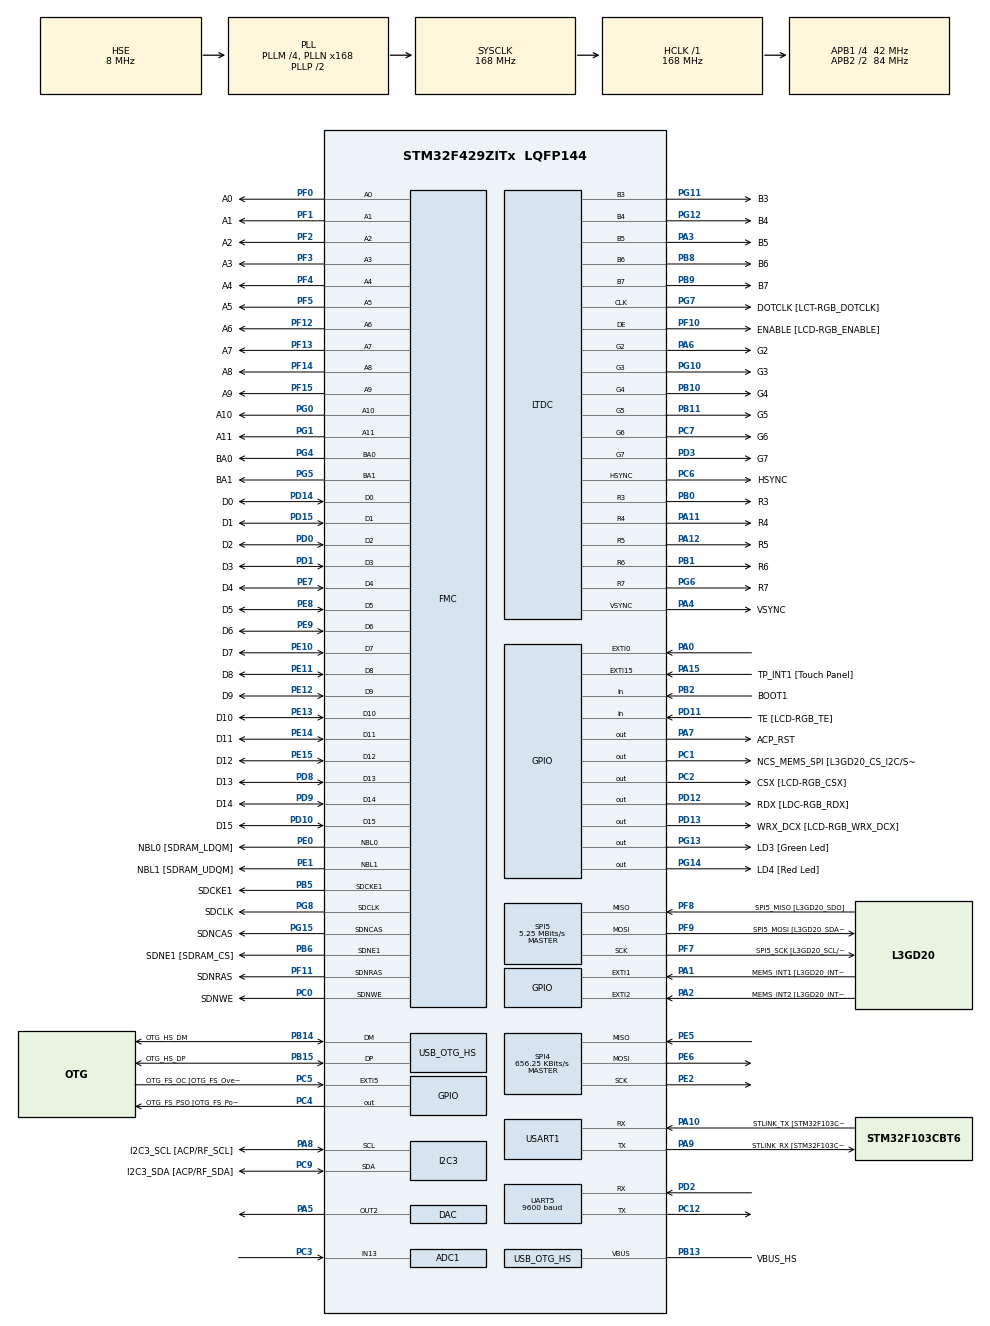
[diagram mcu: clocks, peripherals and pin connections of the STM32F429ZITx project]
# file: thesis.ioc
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ADC1.Channel-0\#ChannelRegularConversion=ADC_CHANNEL_13
ADC1.NbrOfConversionFlag=1
ADC1.Rank-0\#ChannelRegularConversion=1
ADC1.SamplingTime-0\#ChannelRegularConversion=ADC_SAMPLETIME_3CYCLES
ADC1.master=1
FMC.CASLatency1=FMC_SDRAM_CAS_LATENCY_3
FMC.ExitSelfRefreshDelay1=7
FMC.LoadToActiveDelay1=2
FMC.RCDDelay1=2
FMC.RPDelay1=2
FMC.RPDelay2=2
FMC.ReadBurst1=FMC_SDRAM_RBURST_DISABLE
FMC.ReadPipeDelay1=FMC_SDRAM_RPIPE_DELAY_1
FMC.ReadPipeDelay2=FMC_SDRAM_RPIPE_DELAY_1
FMC.RowCycleDelay1=7
FMC.RowCycleDelay2=7
FMC.SDClockPeriod1=FMC_SDRAM_CLOCK_PERIOD_2
FMC.SDClockPeriod2=FMC_SDRAM_CLOCK_PERIOD_2
FMC.SelfRefreshTime1=4
FMC.WriteRecoveryTime1=3
FREERTOS.Tasks01=defaultTask,0,4096,StartDefaultTask,Default,NULL,Dynamic,NULL,NULL
FREERTOS.configCHECK_FOR_STACK_OVERFLOW=2
FREERTOS.configTOTAL_HEAP_SIZE=32768
FREERTOS.configUSE_APPLICATION_TASK_TAG=1
FREERTOS.configUSE_COUNTING_SEMAPHORES=1
FREERTOS.configUSE_IDLE_HOOK=1
FREERTOS.configUSE_MALLOC_FAILED_HOOK=1
FREERTOS.configUSE_RECURSIVE_MUTEXES=1
LTDC.ActiveH=320
LTDC.ActiveW=240
LTDC.Alpha_L0=255
LTDC.BlendingFactor1_L0=LTDC_BLENDING_FACTOR1_PAxCA
LTDC.BlendingFactor2_L0=LTDC_BLENDING_FACTOR2_PAxCA
LTDC.FBStartAdress_L0=0xD0000000
LTDC.HBP=29
LTDC.HFP=10
LTDC.HSync=9
LTDC.ImageHeight_L0=320
LTDC.ImageWidth_L0=240
LTDC.Layers=0
LTDC.PixelFormat_L0=LTDC_PIXEL_FORMAT_RGB565
LTDC.VBP=3
LTDC.VFP=4
LTDC.VSync=1
LTDC.WindowX1_L0=239
LTDC.WindowY1_L0=319
Mcu.Family=STM32F4
Mcu.Name=STM32F429ZITx
Mcu.Package=LQFP144
NVIC.DMA2D_IRQn=true\:5\:0\:true\:false\:true\:true\:true\:true\:true
NVIC.EXTI0_IRQn=true\:5\:0\:false\:false\:true\:true\:true\:true\:true
NVIC.LTDC_IRQn=true\:5\:0\:true\:false\:true\:true\:true\:true\:true
NVIC.OTG_HS_IRQn=true\:5\:0\:false\:false\:true\:true\:true\:true\:true
NVIC.PriorityGroup=NVIC_PRIORITYGROUP_4
NVIC.TIM6_DAC_IRQn=true\:5\:0\:false\:false\:true\:false\:false\:true\:true
NVIC.TIM7_IRQn=true\:5\:0\:false\:false\:true\:true\:true\:true\:true
NVIC.TimeBase=TIM6_DAC_IRQn
NVIC.TimeBaseIP=TIM6
PA0/WKUP.GPIO_ModeDefaultEXTI=GPIO_MODE_IT_RISING
PA0/WKUP.GPIO_PuPd=GPIO_NOPULL
PA0/WKUP.Signal=GPXTI0
PA1.GPIO_Label=MEMS_INT1 [L3GD20_INT1]
PA1.GPIO_ModeDefaultEXTI=GPIO_MODE_IT_FALLING
PA1.GPIO_PuPd=GPIO_PULLUP
PA1.Signal=GPXTI1
PA10.GPIO_Label=STLINK_TX [STM32F103CBT6_PA2]
PA10.Mode=Asynchronous
PA10.Signal=USART1_RX
PA11.GPIO_Label=R4
PA11.GPIO_Mode=GPIO_MODE_AF_PP
PA11.GPIO_PuPd=GPIO_NOPULL
PA11.GPIO_Speed=GPIO_SPEED_FREQ_LOW
PA11.Mode=RGB565
PA11.Signal=LTDC_R4
PA12.GPIO_Label=R5
PA12.GPIO_Mode=GPIO_MODE_AF_PP
PA12.GPIO_PuPd=GPIO_NOPULL
PA12.GPIO_Speed=GPIO_SPEED_FREQ_LOW
PA12.Mode=RGB565
PA12.Signal=LTDC_R5
PA13.GPIO_Label=SWDIO
PA13.Mode=Serial_Wire
PA13.Signal=SYS_JTMS-SWDIO
PA14.GPIO_Label=SWCLK
PA14.Mode=Serial_Wire
PA14.Signal=SYS_JTCK-SWCLK
PA15.GPIO_Label=TP_INT1 [Touch Panel]
PA15.GPIO_ModeDefaultEXTI=GPIO_MODE_EVT_RISING
PA15.GPIO_PuPd=GPIO_NOPULL
PA15.Signal=GPXTI15
PA2.GPIO_Label=MEMS_INT2 [L3GD20_INT2]
PA2.GPIO_ModeDefaultEXTI=GPIO_MODE_EVT_RISING
PA2.GPIO_PuPd=GPIO_NOPULL
PA2.Signal=GPXTI2
PA3.GPIO_Label=B5
PA3.GPIO_Mode=GPIO_MODE_AF_PP
PA3.GPIO_PuPd=GPIO_NOPULL
PA3.GPIO_Speed=GPIO_SPEED_FREQ_LOW
PA3.Mode=RGB565
PA3.Signal=LTDC_B5
PA4.GPIO_Label=VSYNC
PA4.GPIO_Mode=GPIO_MODE_AF_PP
PA4.GPIO_PuPd=GPIO_NOPULL
PA4.GPIO_Speed=GPIO_SPEED_FREQ_LOW
PA4.Mode=RGB565
PA4.Signal=LTDC_VSYNC
PA5.Signal=COMP_DAC2_group
PA6.GPIO_Label=G2
PA6.GPIO_Mode=GPIO_MODE_AF_PP
PA6.GPIO_PuPd=GPIO_NOPULL
PA6.GPIO_Speed=GPIO_SPEED_FREQ_LOW
PA6.Mode=RGB565
PA6.Signal=LTDC_G2
PA7.GPIO_Label=ACP_RST
PA7.GPIO_Mode=GPIO_MODE_OUTPUT_PP
PA7.GPIO_PuPd=GPIO_NOPULL
PA7.GPIO_Speed=GPIO_SPEED_FREQ_LOW
PA7.Signal=GPIO_Output
PA8.GPIO_Label=I2C3_SCL [ACP/RF_SCL]
PA8.GPIO_Mode=GPIO_MODE_AF_OD
PA8.GPIO_Pu=GPIO_PULLUP
PA8.GPIO_PuPd=GPIO_NOPULL
PA8.GPIO_Speed=GPIO_SPEED_FREQ_LOW
PA8.Mode=I2C
PA8.Signal=I2C3_SCL
PA9.GPIO_Label=STLINK_RX [STM32F103CBT6_PA3]
PA9.Mode=Asynchronous
PA9.Signal=USART1_TX
PB0.GPIO_Label=R3
PB0.GPIO_Mode=GPIO_MODE_AF_PP
PB0.GPIO_PuPd=GPIO_NOPULL
PB0.GPIO_Speed=GPIO_SPEED_FREQ_LOW
PB0.Mode=RGB565
PB0.Signal=LTDC_R3
PB1.GPIO_Label=R6
PB1.GPIO_Mode=GPIO_MODE_AF_PP
PB1.GPIO_PuPd=GPIO_NOPULL
PB1.GPIO_Speed=GPIO_SPEED_FREQ_LOW
PB1.Mode=RGB565
PB1.Signal=LTDC_R6
PB10.GPIO_Label=G4
PB10.GPIO_Mode=GPIO_MODE_AF_PP
PB10.GPIO_PuPd=GPIO_NOPULL
PB10.GPIO_Speed=GPIO_SPEED_FREQ_LOW
PB10.Mode=RGB565
PB10.Signal=LTDC_G4
PB11.GPIO_Label=G5
PB11.GPIO_Mode=GPIO_MODE_AF_PP
PB11.GPIO_PuPd=GPIO_NOPULL
PB11.GPIO_Speed=GPIO_SPEED_FREQ_LOW
PB11.Mode=RGB565
PB11.Signal=LTDC_G5
PB12.GPIO_Label=OTG_HS_ID
PB12.GPIO_Mode=GPIO_MODE_AF_PP
PB12.GPIO_PuPd=GPIO_NOPULL
PB12.GPIO_Speed=GPIO_SPEED_FREQ_LOW
PB12.Signal=USB_OTG_HS_ID
PB13.GPIO_Label=VBUS_HS
PB13.GPIO_Mode=GPIO_MODE_INPUT
PB13.GPIO_PuPd=GPIO_NOPULL
PB13.Mode=Activate_VBUS_FS
PB13.Signal=USB_OTG_HS_VBUS
PB14.GPIO_Label=OTG_HS_DM
PB14.GPIO_Mode=GPIO_MODE_AF_PP
PB14.GPIO_PuPd=GPIO_NOPULL
PB14.GPIO_Speed=GPIO_SPEED_FREQ_LOW
PB14.Mode=Host_FS
PB14.Signal=USB_OTG_HS_DM
PB15.GPIO_Label=OTG_HS_DP
PB15.GPIO_Mode=GPIO_MODE_AF_PP
PB15.GPIO_PuPd=GPIO_NOPULL
PB15.GPIO_Speed=GPIO_SPEED_FREQ_LOW
PB15.Mode=Host_FS
PB15.Signal=USB_OTG_HS_DP
PB2/BOOT1.GPIO_Label=BOOT1
PB2/BOOT1.GPIO_Mode=GPIO_MODE_INPUT
PB2/BOOT1.GPIO_PuPd=GPIO_NOPULL
PB2/BOOT1.Signal=GPIO_Input
PB5.GPIO_Label=SDCKE1
PB5.GPIO_Mode=GPIO_MODE_AF_PP
PB5.GPIO_PuPd=GPIO_NOPULL
PB5.GPIO_Speed=GPIO_SPEED_FREQ_VERY_HIGH
PB5.Mode=SdramChipSelect2_1
PB5.Signal=FMC_SDCKE1
PB6.GPIO_Label=SDNE1 [SDRAM_CS]
PB6.GPIO_Mode=GPIO_MODE_AF_PP
PB6.GPIO_PuPd=GPIO_NOPULL
PB6.GPIO_Speed=GPIO_SPEED_FREQ_VERY_HIGH
PB6.Mode=SdramChipSelect2_1
PB6.Signal=FMC_SDNE1
PB8.GPIO_Label=B6
PB8.GPIO_Mode=GPIO_MODE_AF_PP
PB8.GPIO_PuPd=GPIO_NOPULL
PB8.GPIO_Speed=GPIO_SPEED_FREQ_LOW
PB8.Mode=RGB565
PB8.Signal=LTDC_B6
PB9.GPIO_Label=B7
PB9.GPIO_Mode=GPIO_MODE_AF_PP
PB9.GPIO_PuPd=GPIO_NOPULL
PB9.GPIO_Speed=GPIO_SPEED_FREQ_LOW
PB9.Mode=RGB565
PB9.Signal=LTDC_B7
PC0.GPIO_Label=SDNWE
PC0.GPIO_Mode=GPIO_MODE_AF_PP
PC0.GPIO_PuPd=GPIO_NOPULL
PC0.GPIO_Speed=GPIO_SPEED_FREQ_VERY_HIGH
PC0.Signal=FMC_SDNWE
PC1.GPIO_Label=NCS_MEMS_SPI [L3GD20_CS_I2C/SPI]
PC1.GPIO_Mode=GPIO_MODE_OUTPUT_PP
PC1.GPIO_PuPd=GPIO_NOPULL
PC1.GPIO_Speed=GPIO_SPEED_FREQ_LOW
PC1.Signal=GPIO_Output
PC10.GPIO_Label=R2
PC10.GPIO_Mode=GPIO_MODE_AF_PP
PC10.GPIO_PuPd=GPIO_NOPULL
PC10.GPIO_Speed=GPIO_SPEED_FREQ_LOW
PC10.Signal=LTDC_R2
PC12.Mode=Asynchronous
PC12.Signal=UART5_TX
PC14/OSC32_IN.GPIO_Label=PC14-OSC32_IN
PC14/OSC32_IN.Signal=RCC_OSC32_IN
PC15/OSC32_OUT.GPIO_Label=PC15-OSC32_OUT
PC15/OSC32_OUT.Signal=RCC_OSC32_OUT
PC2.GPIO_Label=CSX [LCD-RGB_CSX]
PC2.GPIO_Mode=GPIO_MODE_OUTPUT_PP
PC2.GPIO_PuPd=GPIO_NOPULL
PC2.GPIO_Speed=GPIO_SPEED_FREQ_LOW
PC2.Signal=GPIO_Output
PC3.Signal=ADCx_IN13
PC4.GPIO_Label=OTG_FS_PSO [OTG_FS_PowerSwitchOn]
PC4.GPIO_Mode=GPIO_MODE_OUTPUT_PP
PC4.GPIO_PuPd=GPIO_NOPULL
PC4.GPIO_Speed=GPIO_SPEED_FREQ_LOW
PC4.Signal=GPIO_Output
PC5.GPIO_Label=OTG_FS_OC [OTG_FS_OverCurrent]
PC5.GPIO_ModeDefaultEXTI=GPIO_MODE_EVT_RISING
PC5.Signal=GPXTI5
PC6.GPIO_Label=HSYNC
PC6.GPIO_Mode=GPIO_MODE_AF_PP
PC6.GPIO_PuPd=GPIO_NOPULL
PC6.GPIO_Speed=GPIO_SPEED_FREQ_LOW
PC6.Mode=RGB565
PC6.Signal=LTDC_HSYNC
PC7.GPIO_Label=G6
PC7.GPIO_Mode=GPIO_MODE_AF_PP
PC7.GPIO_PuPd=GPIO_NOPULL
PC7.GPIO_Speed=GPIO_SPEED_FREQ_LOW
PC7.Mode=RGB565
PC7.Signal=LTDC_G6
PC9.GPIO_Label=I2C3_SDA [ACP/RF_SDA]
PC9.GPIO_Mode=GPIO_MODE_AF_OD
PC9.GPIO_Pu=GPIO_PULLUP
PC9.GPIO_PuPd=GPIO_NOPULL
PC9.GPIO_Speed=GPIO_SPEED_FREQ_LOW
PC9.Mode=I2C
PC9.Signal=I2C3_SDA
PD0.GPIO_Label=D2
PD0.GPIO_Mode=GPIO_MODE_AF_PP
PD0.GPIO_PuPd=GPIO_NOPULL
PD0.GPIO_Speed=GPIO_SPEED_FREQ_VERY_HIGH
PD0.Signal=FMC_D2_DA2
PD1.GPIO_Label=D3
PD1.GPIO_Mode=GPIO_MODE_AF_PP
PD1.GPIO_PuPd=GPIO_NOPULL
PD1.GPIO_Speed=GPIO_SPEED_FREQ_VERY_HIGH
PD1.Signal=FMC_D3_DA3
PD10.GPIO_Label=D15
PD10.GPIO_Mode=GPIO_MODE_AF_PP
PD10.GPIO_PuPd=GPIO_NOPULL
PD10.GPIO_Speed=GPIO_SPEED_FREQ_VERY_HIGH
PD10.Signal=FMC_D15_DA15
PD11.GPIO_Label=TE [LCD-RGB_TE]
PD11.GPIO_Mode=GPIO_MODE_INPUT
PD11.GPIO_PuPd=GPIO_NOPULL
PD11.Signal=GPIO_Input
PD12.GPIO_Label=RDX [LDC-RGB_RDX]
PD12.GPIO_Mode=GPIO_MODE_OUTPUT_PP
PD12.GPIO_PuPd=GPIO_NOPULL
PD12.GPIO_Speed=GPIO_SPEED_FREQ_LOW
PD12.Signal=GPIO_Output
PD13.GPIO_Label=WRX_DCX [LCD-RGB_WRX_DCX]
PD13.GPIO_Mode=GPIO_MODE_OUTPUT_PP
PD13.GPIO_PuPd=GPIO_NOPULL
PD13.GPIO_Speed=GPIO_SPEED_FREQ_LOW
PD13.Signal=GPIO_Output
PD14.GPIO_Label=D0
PD14.GPIO_Mode=GPIO_MODE_AF_PP
PD14.GPIO_PuPd=GPIO_NOPULL
PD14.GPIO_Speed=GPIO_SPEED_FREQ_VERY_HIGH
PD14.Signal=FMC_D0_DA0
PD15.GPIO_Label=D1
PD15.GPIO_Mode=GPIO_MODE_AF_PP
PD15.GPIO_PuPd=GPIO_NOPULL
PD15.GPIO_Speed=GPIO_SPEED_FREQ_VERY_HIGH
PD15.Signal=FMC_D1_DA1
PD2.Mode=Asynchronous
PD2.Signal=UART5_RX
PD3.GPIO_Label=G7
PD3.GPIO_Mode=GPIO_MODE_AF_PP
PD3.GPIO_PuPd=GPIO_NOPULL
PD3.GPIO_Speed=GPIO_SPEED_FREQ_LOW
PD3.Mode=RGB565
PD3.Signal=LTDC_G7
PD6.GPIO_Label=B2
PD6.GPIO_Mode=GPIO_MODE_AF_PP
PD6.GPIO_PuPd=GPIO_NOPULL
PD6.GPIO_Speed=GPIO_SPEED_FREQ_LOW
PD6.Signal=LTDC_B2
PD8.GPIO_Label=D13
PD8.GPIO_Mode=GPIO_MODE_AF_PP
PD8.GPIO_PuPd=GPIO_NOPULL
PD8.GPIO_Speed=GPIO_SPEED_FREQ_VERY_HIGH
PD8.Signal=FMC_D13_DA13
PD9.GPIO_Label=D14
PD9.GPIO_Mode=GPIO_MODE_AF_PP
PD9.GPIO_PuPd=GPIO_NOPULL
PD9.GPIO_Speed=GPIO_SPEED_FREQ_VERY_HIGH
PD9.Signal=FMC_D14_DA14
PE0.GPIO_Label=NBL0 [SDRAM_LDQM]
PE0.GPIO_Mode=GPIO_MODE_AF_PP
PE0.GPIO_PuPd=GPIO_NOPULL
PE0.GPIO_Speed=GPIO_SPEED_FREQ_VERY_HIGH
PE0.Signal=FMC_NBL0
PE1.GPIO_Label=NBL1 [SDRAM_UDQM]
PE1.GPIO_Mode=GPIO_MODE_AF_PP
PE1.GPIO_PuPd=GPIO_NOPULL
PE1.GPIO_Speed=GPIO_SPEED_FREQ_VERY_HIGH
PE1.Signal=FMC_NBL1
PE10.GPIO_Label=D7
PE10.GPIO_Mode=GPIO_MODE_AF_PP
PE10.GPIO_PuPd=GPIO_NOPULL
PE10.GPIO_Speed=GPIO_SPEED_FREQ_VERY_HIGH
PE10.Signal=FMC_D7_DA7
PE11.GPIO_Label=D8
PE11.GPIO_Mode=GPIO_MODE_AF_PP
PE11.GPIO_PuPd=GPIO_NOPULL
PE11.GPIO_Speed=GPIO_SPEED_FREQ_VERY_HIGH
PE11.Signal=FMC_D8_DA8
PE12.GPIO_Label=D9
PE12.GPIO_Mode=GPIO_MODE_AF_PP
PE12.GPIO_PuPd=GPIO_NOPULL
PE12.GPIO_Speed=GPIO_SPEED_FREQ_VERY_HIGH
PE12.Signal=FMC_D9_DA9
PE13.GPIO_Label=D10
PE13.GPIO_Mode=GPIO_MODE_AF_PP
PE13.GPIO_PuPd=GPIO_NOPULL
PE13.GPIO_Speed=GPIO_SPEED_FREQ_VERY_HIGH
PE13.Signal=FMC_D10_DA10
PE14.GPIO_Label=D11
PE14.GPIO_Mode=GPIO_MODE_AF_PP
PE14.GPIO_PuPd=GPIO_NOPULL
PE14.GPIO_Speed=GPIO_SPEED_FREQ_VERY_HIGH
PE14.Signal=FMC_D11_DA11
PE15.GPIO_Label=D12
PE15.GPIO_Mode=GPIO_MODE_AF_PP
PE15.GPIO_PuPd=GPIO_NOPULL
PE15.GPIO_Speed=GPIO_SPEED_FREQ_VERY_HIGH
PE15.Signal=FMC_D12_DA12
PE2.Mode=Full_Duplex_Master
PE2.Signal=SPI4_SCK
PE5.Mode=Full_Duplex_Master
PE5.Signal=SPI4_MISO
PE6.Mode=Full_Duplex_Master
PE6.Signal=SPI4_MOSI
PE7.GPIO_Label=D4
PE7.GPIO_Mode=GPIO_MODE_AF_PP
PE7.GPIO_PuPd=GPIO_NOPULL
PE7.GPIO_Speed=GPIO_SPEED_FREQ_VERY_HIGH
PE7.Signal=FMC_D4_DA4
PE8.GPIO_Label=D5
PE8.GPIO_Mode=GPIO_MODE_AF_PP
PE8.GPIO_PuPd=GPIO_NOPULL
PE8.GPIO_Speed=GPIO_SPEED_FREQ_VERY_HIGH
PE8.Signal=FMC_D5_DA5
PE9.GPIO_Label=D6
PE9.GPIO_Mode=GPIO_MODE_AF_PP
PE9.GPIO_PuPd=GPIO_NOPULL
PE9.GPIO_Speed=GPIO_SPEED_FREQ_VERY_HIGH
PE9.Signal=FMC_D6_DA6
PF0.GPIO_Label=A0
PF0.GPIO_Mode=GPIO_MODE_AF_PP
PF0.GPIO_PuPd=GPIO_NOPULL
PF0.GPIO_Speed=GPIO_SPEED_FREQ_VERY_HIGH
PF0.Signal=FMC_A0
PF1.GPIO_Label=A1
PF1.GPIO_Mode=GPIO_MODE_AF_PP
PF1.GPIO_PuPd=GPIO_NOPULL
PF1.GPIO_Speed=GPIO_SPEED_FREQ_VERY_HIGH
PF1.Signal=FMC_A1
PF10.GPIO_Label=ENABLE [LCD-RGB_ENABLE]
PF10.GPIO_Mode=GPIO_MODE_AF_PP
PF10.GPIO_PuPd=GPIO_NOPULL
PF10.GPIO_Speed=GPIO_SPEED_FREQ_LOW
PF10.Mode=RGB565
PF10.Signal=LTDC_DE
PF11.GPIO_Label=SDNRAS
PF11.GPIO_Mode=GPIO_MODE_AF_PP
PF11.GPIO_PuPd=GPIO_NOPULL
PF11.GPIO_Speed=GPIO_SPEED_FREQ_VERY_HIGH
PF11.Signal=FMC_SDNRAS
PF12.GPIO_Label=A6
PF12.GPIO_Mode=GPIO_MODE_AF_PP
PF12.GPIO_PuPd=GPIO_NOPULL
PF12.GPIO_Speed=GPIO_SPEED_FREQ_VERY_HIGH
PF12.Signal=FMC_A6
PF13.GPIO_Label=A7
PF13.GPIO_Mode=GPIO_MODE_AF_PP
PF13.GPIO_PuPd=GPIO_NOPULL
PF13.GPIO_Speed=GPIO_SPEED_FREQ_VERY_HIGH
PF13.Signal=FMC_A7
PF14.GPIO_Label=A8
PF14.GPIO_Mode=GPIO_MODE_AF_PP
PF14.GPIO_PuPd=GPIO_NOPULL
PF14.GPIO_Speed=GPIO_SPEED_FREQ_VERY_HIGH
PF14.Signal=FMC_A8
PF15.GPIO_Label=A9
PF15.GPIO_Mode=GPIO_MODE_AF_PP
PF15.GPIO_PuPd=GPIO_NOPULL
PF15.GPIO_Speed=GPIO_SPEED_FREQ_VERY_HIGH
PF15.Signal=FMC_A9
PF2.GPIO_Label=A2
PF2.GPIO_Mode=GPIO_MODE_AF_PP
PF2.GPIO_PuPd=GPIO_NOPULL
PF2.GPIO_Speed=GPIO_SPEED_FREQ_VERY_HIGH
PF2.Signal=FMC_A2
PF3.GPIO_Label=A3
PF3.GPIO_Mode=GPIO_MODE_AF_PP
PF3.GPIO_PuPd=GPIO_NOPULL
PF3.GPIO_Speed=GPIO_SPEED_FREQ_VERY_HIGH
PF3.Signal=FMC_A3
PF4.GPIO_Label=A4
PF4.GPIO_Mode=GPIO_MODE_AF_PP
PF4.GPIO_PuPd=GPIO_NOPULL
PF4.GPIO_Speed=GPIO_SPEED_FREQ_VERY_HIGH
PF4.Signal=FMC_A4
PF5.GPIO_Label=A5
PF5.GPIO_Mode=GPIO_MODE_AF_PP
PF5.GPIO_PuPd=GPIO_NOPULL
PF5.GPIO_Speed=GPIO_SPEED_FREQ_VERY_HIGH
PF5.Signal=FMC_A5
PF7.GPIO_Label=SPI5_SCK [L3GD20_SCL/SPC]
PF7.GPIO_Mode=GPIO_MODE_AF_PP
PF7.GPIO_PuPd=GPIO_NOPULL
PF7.GPIO_Speed=GPIO_SPEED_FREQ_LOW
PF7.Mode=Full_Duplex_Master
PF7.Signal=SPI5_SCK
PF8.GPIO_Label=SPI5_MISO [L3GD20_SDO]
PF8.GPIO_Mode=GPIO_MODE_AF_PP
PF8.GPIO_PuPd=GPIO_NOPULL
PF8.GPIO_Speed=GPIO_SPEED_FREQ_LOW
PF8.Mode=Full_Duplex_Master
PF8.Signal=SPI5_MISO
PF9.GPIO_Label=SPI5_MOSI [L3GD20_SDA/SDI/SDO]
PF9.GPIO_Mode=GPIO_MODE_AF_PP
PF9.GPIO_PuPd=GPIO_NOPULL
PF9.GPIO_Speed=GPIO_SPEED_FREQ_LOW
PF9.Mode=Full_Duplex_Master
PF9.Signal=SPI5_MOSI
PG0.GPIO_Label=A10
PG0.GPIO_Mode=GPIO_MODE_AF_PP
PG0.GPIO_PuPd=GPIO_NOPULL
PG0.GPIO_Speed=GPIO_SPEED_FREQ_VERY_HIGH
PG0.Signal=FMC_A10
PG1.GPIO_Label=A11
PG1.GPIO_Mode=GPIO_MODE_AF_PP
PG1.GPIO_PuPd=GPIO_NOPULL
PG1.GPIO_Speed=GPIO_SPEED_FREQ_VERY_HIGH
PG1.Signal=FMC_A11
PG10.GPIO_Label=G3
PG10.GPIO_Mode=GPIO_MODE_AF_PP
PG10.GPIO_PuPd=GPIO_NOPULL
PG10.GPIO_Speed=GPIO_SPEED_FREQ_LOW
PG10.Mode=RGB565
PG10.Signal=LTDC_G3
PG11.GPIO_Label=B3
PG11.GPIO_Mode=GPIO_MODE_AF_PP
PG11.GPIO_PuPd=GPIO_NOPULL
PG11.GPIO_Speed=GPIO_SPEED_FREQ_LOW
PG11.Mode=RGB565
PG11.Signal=LTDC_B3
PG12.GPIO_Label=B4
PG12.GPIO_Mode=GPIO_MODE_AF_PP
PG12.GPIO_PuPd=GPIO_NOPULL
PG12.GPIO_Speed=GPIO_SPEED_FREQ_LOW
PG12.Mode=RGB565
PG12.Signal=LTDC_B4
PG13.GPIO_Label=LD3 [Green Led]
PG13.GPIO_Mode=GPIO_MODE_OUTPUT_PP
PG13.GPIO_PuPd=GPIO_NOPULL
PG13.GPIO_Speed=GPIO_SPEED_FREQ_LOW
PG13.Signal=GPIO_Output
PG14.GPIO_Label=LD4 [Red Led]
PG14.GPIO_Mode=GPIO_MODE_OUTPUT_PP
PG14.GPIO_PuPd=GPIO_NOPULL
PG14.GPIO_Speed=GPIO_SPEED_FREQ_LOW
PG14.Signal=GPIO_Output
PG15.GPIO_Label=SDNCAS
PG15.GPIO_Mode=GPIO_MODE_AF_PP
PG15.GPIO_PuPd=GPIO_NOPULL
PG15.GPIO_Speed=GPIO_SPEED_FREQ_VERY_HIGH
PG15.Signal=FMC_SDNCAS
PG4.GPIO_Label=BA0
PG4.GPIO_Mode=GPIO_MODE_AF_PP
PG4.GPIO_PuPd=GPIO_NOPULL
PG4.GPIO_Speed=GPIO_SPEED_FREQ_VERY_HIGH
PG4.Signal=FMC_A14_BA0
PG5.GPIO_Label=BA1
PG5.GPIO_Mode=GPIO_MODE_AF_PP
PG5.GPIO_PuPd=GPIO_NOPULL
PG5.GPIO_Speed=GPIO_SPEED_FREQ_VERY_HIGH
PG5.Signal=FMC_A15_BA1
PG6.GPIO_Label=R7
PG6.GPIO_Mode=GPIO_MODE_AF_PP
PG6.GPIO_PuPd=GPIO_NOPULL
PG6.GPIO_Speed=GPIO_SPEED_FREQ_LOW
PG6.Mode=RGB565
PG6.Signal=LTDC_R7
PG7.GPIO_Label=DOTCLK [LCT-RGB_DOTCLK]
PG7.GPIO_Mode=GPIO_MODE_AF_PP
PG7.GPIO_PuPd=GPIO_NOPULL
PG7.GPIO_Speed=GPIO_SPEED_FREQ_LOW
PG7.Mode=RGB565
PG7.Signal=LTDC_CLK
PG8.GPIO_Label=SDCLK
PG8.GPIO_Mode=GPIO_MODE_AF_PP
PG8.GPIO_PuPd=GPIO_NOPULL
PG8.GPIO_Speed=GPIO_SPEED_FREQ_VERY_HIGH
PG8.Signal=FMC_SDCLK
PH0/OSC_IN.GPIO_Label=PH0-OSC_IN
PH0/OSC_IN.Mode=HSE-External-Oscillator
PH0/OSC_IN.Signal=RCC_OSC_IN
PH1/OSC_OUT.GPIO_Label=PH1-OSC_OUT
PH1/OSC_OUT.Mode=HSE-External-Oscillator
PH1/OSC_OUT.Signal=RCC_OSC_OUT
ProjectManager.HeapSize=0x200
ProjectManager.StackSize=0x400
ProjectManager.TargetToolchain=STM32CubeIDE
RCC.48MHZClocksFreq_Value=48000000
RCC.AHBFreq_Value=168000000
RCC.APB1CLKDivider=RCC_HCLK_DIV4
RCC.APB1Freq_Value=42000000
RCC.APB1TimFreq_Value=84000000
RCC.APB2CLKDivider=RCC_HCLK_DIV2
RCC.APB2Freq_Value=84000000
RCC.APB2TimFreq_Value=168000000
RCC.CortexFreq_Value=168000000
RCC.HCLKFreq_Value=168000000
RCC.HSE_VALUE=8000000
RCC.HSI_VALUE=16000000
RCC.LSE_VALUE=32768
RCC.PLLM=4
RCC.PLLN=168
RCC.PLLQ=7
RCC.PLLSAIN=50
RCC.SYSCLKFreq_VALUE=168000000
RCC.SYSCLKSource=RCC_SYSCLKSOURCE_PLLCLK
RCC.VCOOutputFreq_Value=336000000
SH.ADCx_IN13.0=ADC1_IN13,IN13
SH.COMP_DAC2_group.0=DAC_OUT2,DAC_OUT2
SH.FMC_A0.0=FMC_A0,12b-sda1
SH.FMC_A1.0=FMC_A1,12b-sda1
SH.FMC_A10.0=FMC_A10,12b-sda1
SH.FMC_A11.0=FMC_A11,12b-sda1
SH.FMC_A14_BA0.0=FMC_BA0,FourSdramBanks1
SH.FMC_A15_BA1.0=FMC_BA1,FourSdramBanks1
SH.FMC_A2.0=FMC_A2,12b-sda1
SH.FMC_A3.0=FMC_A3,12b-sda1
SH.FMC_A4.0=FMC_A4,12b-sda1
SH.FMC_A5.0=FMC_A5,12b-sda1
SH.FMC_A6.0=FMC_A6,12b-sda1
SH.FMC_A7.0=FMC_A7,12b-sda1
SH.FMC_A8.0=FMC_A8,12b-sda1
SH.FMC_A9.0=FMC_A9,12b-sda1
SH.FMC_D0_DA0.0=FMC_D0,sd-16b-d1
SH.FMC_D10_DA10.0=FMC_D10,sd-16b-d1
SH.FMC_D11_DA11.0=FMC_D11,sd-16b-d1
SH.FMC_D12_DA12.0=FMC_D12,sd-16b-d1
SH.FMC_D13_DA13.0=FMC_D13,sd-16b-d1
SH.FMC_D14_DA14.0=FMC_D14,sd-16b-d1
SH.FMC_D15_DA15.0=FMC_D15,sd-16b-d1
SH.FMC_D1_DA1.0=FMC_D1,sd-16b-d1
SH.FMC_D2_DA2.0=FMC_D2,sd-16b-d1
SH.FMC_D3_DA3.0=FMC_D3,sd-16b-d1
SH.FMC_D4_DA4.0=FMC_D4,sd-16b-d1
SH.FMC_D5_DA5.0=FMC_D5,sd-16b-d1
SH.FMC_D6_DA6.0=FMC_D6,sd-16b-d1
SH.FMC_D7_DA7.0=FMC_D7,sd-16b-d1
SH.FMC_D8_DA8.0=FMC_D8,sd-16b-d1
SH.FMC_D9_DA9.0=FMC_D9,sd-16b-d1
SH.FMC_NBL0.0=FMC_NBL0,Sd2ByteEnable1
SH.FMC_NBL1.0=FMC_NBL1,Sd2ByteEnable1
SH.FMC_SDCLK.0=FMC_SDCLK,12b-sda1
SH.FMC_SDNCAS.0=FMC_SDNCAS,12b-sda1
SH.FMC_SDNRAS.0=FMC_SDNRAS,12b-sda1
SH.FMC_SDNWE.0=FMC_SDNWE,12b-sda1
SPI4.BaudRatePrescaler=SPI_BAUDRATEPRESCALER_128
SPI4.CalculateBaudRate=656.25 KBits/s
SPI4.Direction=SPI_DIRECTION_2LINES
SPI4.Mode=SPI_MODE_MASTER
SPI4.VirtualType=VM_MASTER
SPI5.BaudRatePrescaler=SPI_BAUDRATEPRESCALER_16
SPI5.CalculateBaudRate=5.25 MBits/s
SPI5.Direction=SPI_DIRECTION_2LINES
SPI5.Mode=SPI_MODE_MASTER
SPI5.VirtualType=VM_MASTER
UART5.BaudRate=9600
UART5.VirtualMode=Asynchronous
USART1.VirtualMode=VM_ASYNC
USB_HOST.BSP.number=1
USB_HOST.USBH_HandleTypeDef-CDC_HS=hUsbHostHS
USB_HOST.VirtualModeHS=Cdc
USB_HOST0.BSP.STBoard=false
USB_HOST0.BSP.api=UnknownBspDriver
USB_HOST0.BSP.instance=PC4
USB_HOST0.BSP.ip=GPIO
USB_HOST0.BSP.mode=Output
USB_HOST0.BSP.name=Drive_VBUS_HS
USB_HOST0.BSP.solution=PC4
USB_OTG_HS.VirtualMode-Host_FS=Host_FS
VP_CRC_VS_CRC.Mode=CRC_Activate
VP_DMA2D_VS_DMA2D.Mode=DMA2D_Activate
VP_FREERTOS_VS_CMSIS_V1.Mode=CMSIS_V1
VP_SYS_VS_tim6.Mode=TIM6
VP_TIM1_VS_ClockSourceINT.Mode=Internal
VP_TIM7_VS_ClockSourceINT.Mode=Enable_Timer
VP_USB_HOST_VS_USB_HOST_CDC_HS.Mode=CDC_HS
board=STM32F429I-DISC1

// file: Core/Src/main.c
/* USER CODE BEGIN Header */
/**
  ******************************************************************************
  * @file           : main.c
  * @brief          : Main program body
  ******************************************************************************
  * @attention
  *
  * Copyright (c) 2025 STMicroelectronics.
  * All rights reserved.
  *
  * This software is licensed under terms that can be found in the LICENSE file
  * in the root directory of this software component.
  * If no LICENSE file comes with this software, it is provided AS-IS.
  *
  ******************************************************************************
  */
/* USER CODE END Header */
#include "main.h"
#include "cmsis_os.h"
#include "usb_host.h"

/* USER CODE BEGIN Includes */
#include <stdio.h>
#include <stdlib.h>
#include <string.h>
#include "dfrobot_bloodoxygen.h"
#include "dfrobot_mlx90614.h"
#include "stm32f429i_discovery.h"
#include "stm32f429i_discovery_lcd.h"
#include "stm32f429i_discovery_ts.h"
#include "max30003.h"
/* USER CODE END Includes */

/* USER CODE BEGIN PD */
#define MAX_RETRIES 3

#define MAX30003_CS_GPIO_Port GPIOC
#define MAX30003_CS_Pin       GPIO_PIN_4
/* USER CODE END PD */

ADC_HandleTypeDef hadc1;

CRC_HandleTypeDef hcrc;

DAC_HandleTypeDef hdac;

DMA2D_HandleTypeDef hdma2d;

I2C_HandleTypeDef hi2c3;

LTDC_HandleTypeDef hltdc;

SPI_HandleTypeDef hspi4;
SPI_HandleTypeDef hspi5;

TIM_HandleTypeDef htim1;
TIM_HandleTypeDef htim7;

UART_HandleTypeDef huart5;
UART_HandleTypeDef huart1;

SDRAM_HandleTypeDef hsdram1;

osThreadId defaultTaskHandle;
/* USER CODE BEGIN PV */
uint32_t rtc_base_time = 0;
osThreadId myTaskHandle;
osThreadId touchTaskHandle;
osThreadId renderTaskHandle;

float CFG_TEMP_HIGH = 37.5f;
float CFG_TEMP_LOW  = 35.0f;

int32_t CFG_SPO2_LOW = 92;
int32_t CFG_HR_HIGH  = 120;
int32_t CFG_HR_LOW   = 40;

int32_t CFG_GSR_STRESS = 600;
int32_t CFG_GSR_NEUTRAL = 1000;

volatile uint8_t systemState = 1;
volatile uint8_t systemStartupComplete = 0;

#define BLOOD_OXY_BUFFER_SIZE 5
typedef struct {
    int16_t spo2_values[BLOOD_OXY_BUFFER_SIZE];
    int32_t hr_values[BLOOD_OXY_BUFFER_SIZE];
    uint8_t valid_count;
    int16_t last_valid_spo2;
    int32_t last_valid_hr;
} BloodOxyBuffer;

typedef struct {
    uint32_t value;
    char mood[16];
} GSR_Data_t;

volatile GSR_Data_t gsrData;

static BloodOxyBuffer bloodOxyBuffer = {0};
volatile uint8_t measurementActive = 1;
volatile uint8_t updateScreenFlag = 0;
osMessageQId ecgQueueHandle;
osMessageQId tempQueueHandle;
osMessageQId oxyQueueHandle;
osMessageQId gsrQueueHandle;

MAX30003_Ctx max30003;

#define BUTTON_AREA_Y_START 270
#define BUTTON_HEIGHT       50
#define BUTTON_WIDTH        80
/* USER CODE END PV */

void SystemClock_Config(void);
static void MX_GPIO_Init(void);
static void MX_CRC_Init(void);
static void MX_DMA2D_Init(void);
static void MX_FMC_Init(void);
static void MX_I2C3_Init(void);
static void MX_LTDC_Init(void);
static void MX_SPI5_Init(void);
static void MX_TIM1_Init(void);
static void MX_USART1_UART_Init(void);
static void MX_TIM7_Init(void);
static void MX_DAC_Init(void);
static void MX_UART5_Init(void);
static void MX_ADC1_Init(void);
static void MX_SPI4_Init(void);
void StartDefaultTask(const void *argument);

/* USER CODE BEGIN PFP */
uint8_t calcChecksum(const char* str, size_t len);
bool waitForAck(UART_HandleTypeDef* uart, uint32_t timeout_ms);

void StartTouchTask(const void *argument);
void StartRenderTask(const void *argument);

void DrawHeader(void);
void DrawBottomButtons(void);
uint8_t MAX30003_GetECG_Sample(MAX30003_Ctx *ctx, int32_t *sample);
/* USER CODE END PFP */

/* USER CODE BEGIN 0 */
#ifdef __GNUC__
/* With GCC/RAISONANCE, small printf (option LD Linker->Libraries->Small printf
   set to 'Yes') calls __io_putchar() */
int __io_putchar(int ch)
{
  HAL_UART_Transmit(&huart1, (uint8_t *)&ch, 1, HAL_MAX_DELAY);
  return ch;
}
#else
int fputc(int ch, FILE *f)
{
  HAL_UART_Transmit(&huart1, (uint8_t *)&ch, 1, HAL_MAX_DELAY);
  return ch;
}
#endif

volatile uint8_t currentSensor = 0;

extern uint32_t rtc_base_time;

MLX90614_Data mlxData;
BoodOxyData oxyData;
extern uint16_t lcdHeight;

void StartRenderTask(const void *argument)
{
	while (systemStartupComplete == 0) {
	        osDelay(50);
	    }
    // Start systemu
    BSP_LCD_DisplayOn();
    BSP_LCD_Clear(LCD_COLOR_BLACK);
    DrawHeader();
    DrawBottomButtons();

    const uint16_t GRAPH_TOP = 35;
    const uint16_t GRAPH_BOT = 270;
    static uint16_t x = 0;
    static uint16_t lastY = 160;
    static uint8_t lastSensor = 255;
    static uint8_t lastSystemState = 1;

    for (;;)
    {
        // ==========================================================
        // 1. ZARZĄDZANIE ENERGIĄ (SUSPEND / RESUME)
        // ==========================================================

        // --- PRZEJŚCIE W STAN OFF ---
        if (systemState == 0)
        {
            if (lastSystemState == 1)
            {
                // 1. Zamaluj ekran na czarno (blokada światła)
                BSP_LCD_Clear(LCD_COLOR_BLACK);

                // 2. ZATRZYMAJ INNE TASKI (Usypiamy sensory i dotyk)
                // Dzięki temu myTask nie mieli w kółko I2C, a touchTask nie mieli SPI.
                osThreadSuspend(myTaskHandle);
                osThreadSuspend(touchTaskHandle);

                lastSystemState = 0;
            }

            // RenderTask też idzie spać (czeka na zmianę flagi), odświeżanie co 200ms
            osDelay(200);
            continue;
        }

        // --- PRZEJŚCIE W STAN ON ---
        else if (systemState == 1 && lastSystemState == 0)
        {
            // 1. WZNÓW INNE TASKI (Budzimy je)
            osThreadResume(myTaskHandle);
            osThreadResume(touchTaskHandle);

            // 2. Przywróć ekran
            BSP_LCD_DisplayOn();
            osDelay(100);
            BSP_LCD_Clear(LCD_COLOR_BLACK);
            DrawHeader();
            DrawBottomButtons();

            BSP_LCD_SetBackColor(LCD_COLOR_BLACK);
            BSP_LCD_SetTextColor(0xFFFFFFFF); // Biały
            BSP_LCD_SetFont(&Font24);
            BSP_LCD_DisplayStringAt(0, 120, (uint8_t*)"SYSTEM WAKEUP", CENTER_MODE);

            // 3. Reset zmiennych, żeby wykresy nie wariowały
            x = 0;
            osDelay(500);
            updateScreenFlag = 1; // Wymuś narysowanie właściwego ekranu
            lastSystemState = 1;
        }

        // ==========================================================
        // 2. NORMALNA PRACA (Reszta kodu bez zmian)
        // ==========================================================

        // Zmiana Sensora
        if (currentSensor != lastSensor)
        {
            BSP_LCD_Clear(LCD_COLOR_BLACK);
            DrawHeader();
            DrawBottomButtons();

            if (measurementActive) {
                BSP_LCD_SetBackColor(LCD_COLOR_BLACK);
                BSP_LCD_SetTextColor(LCD_COLOR_YELLOW);
                BSP_LCD_SetFont(&Font16);

                if(currentSensor == 1) BSP_LCD_DisplayStringAt(0, 100, (uint8_t*)"Place Finger...", CENTER_MODE);
                else if(currentSensor == 3) BSP_LCD_DisplayStringAt(0, 100, (uint8_t*)"Initializing ECG...", CENTER_MODE);
                else BSP_LCD_DisplayStringAt(0, 100, (uint8_t*)"Measuring...", CENTER_MODE);
            }
            lastSensor = currentSensor;
            updateScreenFlag = 0;
            x = 0;
        }
        // Start / Stop (Pauza na ekranie)
        else if (updateScreenFlag)
        {
            if (!measurementActive) // PAUZA
            {
                DrawBottomButtons();
                BSP_LCD_SetTextColor(LCD_COLOR_BLACK); BSP_LCD_FillRect(50, 110, 140, 60);
                BSP_LCD_SetTextColor(LCD_COLOR_WHITE); // Ramka (Czerwona)

                BSP_LCD_DrawRect(50, 110, 140, 60);
                BSP_LCD_DrawRect(51, 111, 138, 58);

                BSP_LCD_SetBackColor(LCD_COLOR_BLACK);
                BSP_LCD_SetTextColor(LCD_COLOR_RED);
                BSP_LCD_SetFont(&Font24);
                BSP_LCD_DisplayStringAt(0, 128, (uint8_t*)"PAUSED", CENTER_MODE);
            }
            else
            {
                BSP_LCD_Clear(LCD_COLOR_BLACK); DrawHeader(); DrawBottomButtons();
                BSP_LCD_SetBackColor(LCD_COLOR_BLACK); BSP_LCD_SetTextColor(LCD_COLOR_YELLOW); BSP_LCD_SetFont(&Font16);
                if(currentSensor == 1) BSP_LCD_DisplayStringAt(0, 100, (uint8_t*)"Place Finger...", CENTER_MODE);
                else BSP_LCD_DisplayStringAt(0, 100, (uint8_t*)"Measuring...", CENTER_MODE);
                x = 0;
            }
            updateScreenFlag = 0;
        }

        if (currentSensor == 0) {
                     osEvent evt = osMessageGet(tempQueueHandle, 10);
                     if (evt.status == osEventMessage) {
                         MLX90614_Data *pData = (MLX90614_Data*)evt.value.v;

                         // Tło
                         BSP_LCD_SetTextColor(LCD_COLOR_BLACK); BSP_LCD_FillRect(0, 80, 240, 60);
                         BSP_LCD_SetBackColor(LCD_COLOR_BLACK);

                         // Wyświetlanie Ambient (zazwyczaj mniej ważne)
                         BSP_LCD_SetTextColor(LCD_COLOR_WHITE);
                         BSP_LCD_SetFont(&Font16);
                         char buf[32];
                         snprintf(buf, sizeof(buf), "Ambient: %.2f C", pData->ambient);
                         BSP_LCD_DisplayStringAt(0, 80, (uint8_t*)buf, CENTER_MODE);

                         // --- LOGIKA ALARMU WIZUALNEGO ---
                         if (pData->object >= CFG_TEMP_HIGH || pData->object <= CFG_TEMP_LOW) {
                             BSP_LCD_SetTextColor(LCD_COLOR_RED); // ALARM!
                         } else {
                             BSP_LCD_SetTextColor(LCD_COLOR_GREEN); // OK
                         }
                         // -------------------------------

                         snprintf(buf, sizeof(buf), "Object : %.2f C", pData->object);
                         BSP_LCD_DisplayStringAt(0, 110, (uint8_t*)buf, CENTER_MODE);
                     }
                }
        else if (currentSensor == 1) {
                     osEvent evt = osMessageGet(oxyQueueHandle, 10);
                     if (evt.status == osEventMessage) {
                         BoodOxyData *pData = (BoodOxyData*)evt.value.v;
                         BSP_LCD_SetTextColor(LCD_COLOR_BLACK); BSP_LCD_FillRect(0, 80, 240, 120);
                         BSP_LCD_SetBackColor(LCD_COLOR_BLACK); BSP_LCD_SetFont(&Font16);
                         char buf[32];

                         // --- LOGIKA ALARMU DLA SPO2 ---
                         if (pData->spo2 < CFG_SPO2_LOW) BSP_LCD_SetTextColor(LCD_COLOR_RED);
                         else BSP_LCD_SetTextColor(LCD_COLOR_WHITE);

                         snprintf(buf, sizeof(buf), "SpO2 : %d %%", pData->spo2);
                         BSP_LCD_DisplayStringAt(0, 80, (uint8_t*)buf, CENTER_MODE);

                         // --- LOGIKA ALARMU DLA HR ---
                         if (pData->heartbeat > CFG_HR_HIGH || pData->heartbeat < CFG_HR_LOW)
                             BSP_LCD_SetTextColor(LCD_COLOR_RED);
                         else
                             BSP_LCD_SetTextColor(LCD_COLOR_WHITE);

                         snprintf(buf, sizeof(buf), "HR   : %ld bpm", pData->heartbeat);
                         BSP_LCD_DisplayStringAt(0, 110, (uint8_t*)buf, CENTER_MODE);

                         BSP_LCD_SetTextColor(LCD_COLOR_GREEN);
                         BSP_LCD_DisplayStringAt(0, 140, (uint8_t*)"RESULT READY", CENTER_MODE);
                     }
                }
        else if (currentSensor == 2) {
             osEvent evt = osMessageGet(gsrQueueHandle, 10);
             if (evt.status == osEventMessage) {
                 GSR_Data_t *pData = (GSR_Data_t*)evt.value.v;
                 BSP_LCD_SetTextColor(LCD_COLOR_BLACK); BSP_LCD_FillRect(0, 80, 240, 60);
                 BSP_LCD_SetBackColor(LCD_COLOR_BLACK); BSP_LCD_SetTextColor(0xFFFFFFFF); BSP_LCD_SetFont(&Font16);
                 char buf[32];
                 snprintf(buf, sizeof(buf), "GSR Avg: %lu", pData->value);
                 BSP_LCD_DisplayStringAt(0, 80, (uint8_t*)buf, CENTER_MODE);

                 if (strcmp((char*)pData->mood, "Stressed") == 0) BSP_LCD_SetTextColor(LCD_COLOR_RED); // Czerwony
                 else if (strcmp((char*)pData->mood, "Relaxed") == 0) BSP_LCD_SetTextColor(LCD_COLOR_GREEN); // Zielony
                 else BSP_LCD_SetTextColor(LCD_COLOR_WHITE);

                 snprintf(buf, sizeof(buf), "Mood: %s", pData->mood);
                 BSP_LCD_DisplayStringAt(0, 110, (uint8_t*)buf, CENTER_MODE);
             }
        }
        else if (currentSensor == 3) {
             osEvent evt = osMessageGet(ecgQueueHandle, 2);
             if (evt.status == osEventMessage) {
                if(x==0) { BSP_LCD_SetTextColor(LCD_COLOR_BLACK); BSP_LCD_FillRect(0, 80, 240, 40); }
                int32_t val = evt.value.v;
                int16_t newY = 160 - (val / 35);
                if (newY < GRAPH_TOP) {
                    newY = GRAPH_TOP;
                }
                if (newY > GRAPH_BOT) {
                    newY = GRAPH_BOT;
                }
                BSP_LCD_SetTextColor(LCD_COLOR_BLACK); BSP_LCD_FillRect(x+1, GRAPH_TOP, 10, GRAPH_BOT-GRAPH_TOP);
                BSP_LCD_SetTextColor(LCD_COLOR_GREEN); // Zielony wykres
                if(x>0) BSP_LCD_DrawLine(x-1, lastY, x, newY);
                lastY = newY; x++;
                if (x >= 240) x = 0;
             }
        }
    }
}

void HAL_GPIO_EXTI_Callback(uint16_t GPIO_Pin)
{
    // =========================================================
    // 1. OBSŁUGA KABLA WIFI (PC1) - TO JEST NOWE
    // =========================================================
    if (GPIO_Pin == GPIO_PIN_1)
    {
        // Sprawdzamy czy stan jest NISKI (0V = Brak WiFi)
        if (HAL_GPIO_ReadPin(GPIOC, GPIO_PIN_1) == GPIO_PIN_RESET)
        {
            printf("!!! HARDWARE SIGNAL: WIFI LOST !!!\r\n");

            // 1. Zatrzymaj pomiary i wyczyść bufory
            measurementActive = 0;
            memset(&bloodOxyBuffer, 0, sizeof(BloodOxyBuffer));

            // 2. Rysuj CZERWONY EKRAN (NO WIFI)
            BSP_LCD_Clear(LCD_COLOR_BLUE);
            BSP_LCD_SetBackColor(LCD_COLOR_RED);
            BSP_LCD_SetTextColor(LCD_COLOR_WHITE);

            BSP_LCD_SetFont(&Font24);
            BSP_LCD_DisplayStringAt(0, 120, (uint8_t*)"NO WIFI", CENTER_MODE);

            BSP_LCD_SetFont(&Font16);
            BSP_LCD_DisplayStringAt(0, 160, (uint8_t*)"Connection Lost...", CENTER_MODE);

            while (HAL_GPIO_ReadPin(GPIOC, GPIO_PIN_1) == GPIO_PIN_RESET)
            {
                HAL_GPIO_TogglePin(GPIOG, LD3_Pin);

                for(volatile int i=0; i<1000000; i++);
            }

            printf("!!! HARDWARE SIGNAL: WIFI RESTORED !!!\r\n");

            BSP_LCD_Clear(LCD_COLOR_BLACK);
            DrawHeader();
            DrawBottomButtons();
            updateScreenFlag = 1;
        }
    }

    // =========================================================
    // 2. OBSŁUGA PRZYCISKU (PA0) - STARY KOD
    // =========================================================
    if (GPIO_Pin == GPIO_PIN_0) {
		static uint32_t last_tick = 0;
		if (HAL_GetTick() - last_tick > 200)
		{
			systemState = !systemState;

			if (systemState) {
				printf("SYSTEM: POWER ON\r\n");
				HAL_GPIO_WritePin(GPIOG, LD3_Pin, GPIO_PIN_SET);
			} else {
				printf("SYSTEM: POWER OFF (Standby)\r\n");
				HAL_GPIO_WritePin(GPIOG, LD3_Pin, GPIO_PIN_RESET);

				measurementActive = 0;
				memset(&bloodOxyBuffer, 0, sizeof(BloodOxyBuffer));
			}

			updateScreenFlag = 1;
			last_tick = HAL_GetTick();
		}
    }
}

void myStartDefaultTask(const void *argument);
/* USER CODE END 0 */

int main(void)
{

  /* USER CODE BEGIN 1 */
	__HAL_RCC_PWR_CLK_ENABLE();
	HAL_PWR_DisableWakeUpPin(PWR_WAKEUP_PIN1);
  /* USER CODE END 1 */

  /* MCU Configuration--------------------------------------------------------*/

  /* Reset of all peripherals, Initializes the Flash interface and the Systick. */
  HAL_Init();

  /* Configure the system clock */
  SystemClock_Config();

  /* USER CODE BEGIN SysInit */
  HAL_GPIO_WritePin(ACP_RST_GPIO_Port, ACP_RST_Pin, GPIO_PIN_RESET);
  HAL_Delay(20);
  HAL_GPIO_WritePin(ACP_RST_GPIO_Port, ACP_RST_Pin, GPIO_PIN_SET);
  HAL_Delay(20);
  /* USER CODE END SysInit */

  /* Initialize all configured peripherals */
  MX_GPIO_Init();
  MX_CRC_Init();
  MX_DMA2D_Init();
  MX_FMC_Init();
  MX_I2C3_Init();
  MX_LTDC_Init();
  MX_SPI5_Init();
  MX_TIM1_Init();
  MX_USART1_UART_Init();
  MX_TIM7_Init();
  MX_DAC_Init();
  MX_UART5_Init();
  MX_ADC1_Init();
  MX_SPI4_Init();
  /* USER CODE BEGIN 2 */

  HAL_GPIO_WritePin(GPIOG, LD3_Pin, GPIO_PIN_SET);
    #define LAYER0_ADDRESS  0xD0000000
    #define LAYER1_ADDRESS  (0xD0000000 + 0x25800)

//    LTDC_LayerCfgTypeDef pLayerCfg = {0};

    BSP_LCD_MspInit();

    hltdc.Instance = LTDC;
    hltdc.Init.HSPolarity = LTDC_HSPOLARITY_AL;
    hltdc.Init.VSPolarity = LTDC_VSPOLARITY_AL;
    hltdc.Init.DEPolarity = LTDC_DEPOLARITY_AL;
    hltdc.Init.PCPolarity = LTDC_PCPOLARITY_IPC;
    hltdc.Init.HorizontalSync = 9;
    hltdc.Init.VerticalSync = 1;
    hltdc.Init.AccumulatedHBP = 29;
    hltdc.Init.AccumulatedVBP = 3;
    hltdc.Init.AccumulatedActiveW = 269;
    hltdc.Init.AccumulatedActiveH = 323;
    hltdc.Init.TotalWidth = 279;
    hltdc.Init.TotalHeigh = 327;

    hltdc.Init.Backcolor.Blue = 0;
    hltdc.Init.Backcolor.Green = 0;
    hltdc.Init.Backcolor.Red = 0;

    RCC_PeriphCLKInitTypeDef PeriphClkInitStruct = {0};
    PeriphClkInitStruct.PeriphClockSelection = RCC_PERIPHCLK_LTDC;
    PeriphClkInitStruct.PLLSAI.PLLSAIN = 192;
    PeriphClkInitStruct.PLLSAI.PLLSAIR = 4;
    PeriphClkInitStruct.PLLSAIDivR = RCC_PLLSAIDIVR_8;
    HAL_RCCEx_PeriphCLKConfig(&PeriphClkInitStruct);

    HAL_LTDC_Init(&hltdc);
    ili9341_Init();
    BSP_SDRAM_Init();

    memset((void*)LAYER0_ADDRESS, 0, 240 * 320 * 2 * 2);

    BSP_LCD_Init();
    BSP_LCD_LayerDefaultInit(0, LAYER0_ADDRESS);
    BSP_LCD_SelectLayer(0);
    BSP_LCD_SetLayerVisible(0, ENABLE);
    BSP_LCD_SetColorKeying(0, LCD_COLOR_BLACK);
    HAL_LTDC_DisableColorKeying(&hltdc, 0);
    BSP_LCD_Clear(LCD_COLOR_BLACK);

    BSP_LCD_LayerDefaultInit(1, LAYER1_ADDRESS);
    BSP_LCD_SelectLayer(1);
    BSP_LCD_SetLayerVisible(1, ENABLE);
    BSP_LCD_SetTransparency(1, 255);

    HAL_LTDC_DisableColorKeying(&hltdc, 1);

    ili9341_DisplayOn();

    BSP_LCD_SelectLayer(1);

  BSP_LCD_Clear(LCD_COLOR_BLACK);

  BSP_LCD_SetTextColor(LCD_COLOR_RED);
  BSP_LCD_FillRect(10, 100, 220, 120);

      BSP_LCD_SetTextColor(LCD_COLOR_WHITE);
      BSP_LCD_DrawRect(10, 100, 220, 120);

      BSP_LCD_SetBackColor(LCD_COLOR_GREEN);
      BSP_LCD_SetTextColor(LCD_COLOR_BLACK);

      BSP_LCD_SetFont(&Font20);

      BSP_LCD_DisplayStringAt(0, 130, (uint8_t*)"SYSTEM START UP", CENTER_MODE);

      BSP_LCD_SetFont(&Font16);
      BSP_LCD_DisplayStringAt(0, 160, (uint8_t*)"Please wait...", CENTER_MODE);

      if (BSP_TS_Init(240, 320) == TS_OK) {
          printf("TS init OK\r\n");
      }
    /* USER CODE END 2 */

  /* USER CODE BEGIN RTOS_QUEUES */
  /* add queues, ... */
  osMessageQDef(ecgQueue, 64, int32_t);
  ecgQueueHandle = osMessageCreate(osMessageQ(ecgQueue), NULL);

  osMessageQDef(tempQueue, 1, uint32_t);
  tempQueueHandle = osMessageCreate(osMessageQ(tempQueue), NULL);

  osMessageQDef(oxyQueue, 1, uint32_t);
  oxyQueueHandle = osMessageCreate(osMessageQ(oxyQueue), NULL);

  osMessageQDef(gsrQueue, 1, uint32_t);
  gsrQueueHandle = osMessageCreate(osMessageQ(gsrQueue), NULL);

  /* USER CODE END RTOS_QUEUES */

  /* Create the thread(s) */
  /* definition and creation of defaultTask */
  osThreadDef(defaultTask, StartDefaultTask, osPriorityNormal, 0, 512);
  defaultTaskHandle = osThreadCreate(osThread(defaultTask), NULL);

  /* USER CODE BEGIN RTOS_THREADS */
  /* add threads, ... */
  osThreadDef(myTask, myStartDefaultTask, osPriorityLow, 0, 4096);
  myTaskHandle = osThreadCreate(osThread(myTask), NULL);

  osThreadDef(touchTask, StartTouchTask, osPriorityLow, 0, 2048);
  touchTaskHandle = osThreadCreate(osThread(touchTask), NULL);

  osThreadDef(renderTask, StartRenderTask, osPriorityBelowNormal, 0, 512);
  renderTaskHandle = osThreadCreate(osThread(renderTask), NULL);
  /* USER CODE END RTOS_THREADS */

  /* Start scheduler */
  osKernelStart();

  /* We should never get here as control is now taken by the scheduler */

  /* Infinite loop */
  while (1)
  {

  }
}

void SystemClock_Config(void)
{
  RCC_OscInitTypeDef RCC_OscInitStruct = {0};
  RCC_ClkInitTypeDef RCC_ClkInitStruct = {0};

  /** Configure the main internal regulator output voltage
  */
  __HAL_RCC_PWR_CLK_ENABLE();
  __HAL_PWR_VOLTAGESCALING_CONFIG(PWR_REGULATOR_VOLTAGE_SCALE1);

  /** Initializes the RCC Oscillators according to the specified parameters
  * in the RCC_OscInitTypeDef structure.
  */
  RCC_OscInitStruct.OscillatorType = RCC_OSCILLATORTYPE_HSE;
  RCC_OscInitStruct.HSEState = RCC_HSE_ON;
  RCC_OscInitStruct.PLL.PLLState = RCC_PLL_ON;
  RCC_OscInitStruct.PLL.PLLSource = RCC_PLLSOURCE_HSE;
  RCC_OscInitStruct.PLL.PLLM = 4;
  RCC_OscInitStruct.PLL.PLLN = 168;
  RCC_OscInitStruct.PLL.PLLP = RCC_PLLP_DIV2;
  RCC_OscInitStruct.PLL.PLLQ = 7;
  if (HAL_RCC_OscConfig(&RCC_OscInitStruct) != HAL_OK)
  {
    Error_Handler();
  }

  /** Initializes the CPU, AHB and APB buses clocks
  */
  RCC_ClkInitStruct.ClockType = RCC_CLOCKTYPE_HCLK|RCC_CLOCKTYPE_SYSCLK
                              |RCC_CLOCKTYPE_PCLK1|RCC_CLOCKTYPE_PCLK2;
  RCC_ClkInitStruct.SYSCLKSource = RCC_SYSCLKSOURCE_PLLCLK;
  RCC_ClkInitStruct.AHBCLKDivider = RCC_SYSCLK_DIV1;
  RCC_ClkInitStruct.APB1CLKDivider = RCC_HCLK_DIV4;
  RCC_ClkInitStruct.APB2CLKDivider = RCC_HCLK_DIV2;

  if (HAL_RCC_ClockConfig(&RCC_ClkInitStruct, FLASH_LATENCY_5) != HAL_OK)
  {
    Error_Handler();
  }
}

static void MX_ADC1_Init(void)
{

  ADC_ChannelConfTypeDef sConfig = {0};

  /** Configure the global features of the ADC (Clock, Resolution, Data Alignment and number of conversion)
  */
  hadc1.Instance = ADC1;
  hadc1.Init.ClockPrescaler = ADC_CLOCK_SYNC_PCLK_DIV4;
  hadc1.Init.Resolution = ADC_RESOLUTION_12B;
  hadc1.Init.ScanConvMode = DISABLE;
  hadc1.Init.ContinuousConvMode = DISABLE;
  hadc1.Init.DiscontinuousConvMode = DISABLE;
  hadc1.Init.ExternalTrigConvEdge = ADC_EXTERNALTRIGCONVEDGE_NONE;
  hadc1.Init.ExternalTrigConv = ADC_SOFTWARE_START;
  hadc1.Init.DataAlign = ADC_DATAALIGN_RIGHT;
  hadc1.Init.NbrOfConversion = 1;
  hadc1.Init.DMAContinuousRequests = DISABLE;
  hadc1.Init.EOCSelection = ADC_EOC_SINGLE_CONV;
  if (HAL_ADC_Init(&hadc1) != HAL_OK)
  {
    Error_Handler();
  }

  /** Configure for the selected ADC regular channel its corresponding rank in the sequencer and its sample time.
  */
  sConfig.Channel = ADC_CHANNEL_13;
  sConfig.Rank = 1;
  sConfig.SamplingTime = ADC_SAMPLETIME_3CYCLES;
  if (HAL_ADC_ConfigChannel(&hadc1, &sConfig) != HAL_OK)
  {
    Error_Handler();
  }

}

static void MX_CRC_Init(void)
{

  hcrc.Instance = CRC;
  if (HAL_CRC_Init(&hcrc) != HAL_OK)
  {
    Error_Handler();
  }

}

static void MX_DAC_Init(void)
{

  DAC_ChannelConfTypeDef sConfig = {0};

  /** DAC Initialization
  */
  hdac.Instance = DAC;
  if (HAL_DAC_Init(&hdac) != HAL_OK)
  {
    Error_Handler();
  }

  /** DAC channel OUT2 config
  */
  sConfig.DAC_Trigger = DAC_TRIGGER_NONE;
  sConfig.DAC_OutputBuffer = DAC_OUTPUTBUFFER_ENABLE;
  if (HAL_DAC_ConfigChannel(&hdac, &sConfig, DAC_CHANNEL_2) != HAL_OK)
  {
    Error_Handler();
  }

}

static void MX_DMA2D_Init(void)
{

  hdma2d.Instance = DMA2D;
  hdma2d.Init.Mode = DMA2D_M2M;
  hdma2d.Init.ColorMode = DMA2D_OUTPUT_ARGB8888;
  hdma2d.Init.OutputOffset = 0;
  hdma2d.LayerCfg[1].InputOffset = 0;
  hdma2d.LayerCfg[1].InputColorMode = DMA2D_INPUT_ARGB8888;
  hdma2d.LayerCfg[1].AlphaMode = DMA2D_NO_MODIF_ALPHA;
  hdma2d.LayerCfg[1].InputAlpha = 0;
  if (HAL_DMA2D_Init(&hdma2d) != HAL_OK)
  {
    Error_Handler();
  }
  if (HAL_DMA2D_ConfigLayer(&hdma2d, 1) != HAL_OK)
  {
    Error_Handler();
  }

}

static void MX_I2C3_Init(void)
{

  hi2c3.Instance = I2C3;
  hi2c3.Init.ClockSpeed = 100000;
  hi2c3.Init.DutyCycle = I2C_DUTYCYCLE_2;
  hi2c3.Init.OwnAddress1 = 0;
  hi2c3.Init.AddressingMode = I2C_ADDRESSINGMODE_7BIT;
  hi2c3.Init.DualAddressMode = I2C_DUALADDRESS_DISABLE;
  hi2c3.Init.OwnAddress2 = 0;
  hi2c3.Init.GeneralCallMode = I2C_GENERALCALL_DISABLE;
  hi2c3.Init.NoStretchMode = I2C_NOSTRETCH_DISABLE;
  if (HAL_I2C_Init(&hi2c3) != HAL_OK)
  {
    Error_Handler();
  }

  /** Configure Analogue filter
  */
  if (HAL_I2CEx_ConfigAnalogFilter(&hi2c3, I2C_ANALOGFILTER_ENABLE) != HAL_OK)
  {
    Error_Handler();
  }

  /** Configure Digital filter
  */
  if (HAL_I2CEx_ConfigDigitalFilter(&hi2c3, 0) != HAL_OK)
  {
    Error_Handler();
  }

}

static void MX_LTDC_Init(void)
{

  LTDC_LayerCfgTypeDef pLayerCfg = {0};

  hltdc.Instance = LTDC;
  hltdc.Init.HSPolarity = LTDC_HSPOLARITY_AL;
  hltdc.Init.VSPolarity = LTDC_VSPOLARITY_AL;
  hltdc.Init.DEPolarity = LTDC_DEPOLARITY_AL;
  hltdc.Init.PCPolarity = LTDC_PCPOLARITY_IPC;
  hltdc.Init.HorizontalSync = 8;
  hltdc.Init.VerticalSync = 0;
  hltdc.Init.AccumulatedHBP = 37;
  hltdc.Init.AccumulatedVBP = 3;
  hltdc.Init.AccumulatedActiveW = 277;
  hltdc.Init.AccumulatedActiveH = 323;
  hltdc.Init.TotalWidth = 287;
  hltdc.Init.TotalHeigh = 327;
  hltdc.Init.Backcolor.Blue = 0;
  hltdc.Init.Backcolor.Green = 0;
  hltdc.Init.Backcolor.Red = 0;
  if (HAL_LTDC_Init(&hltdc) != HAL_OK)
  {
    Error_Handler();
  }
  pLayerCfg.WindowX0 = 0;
  pLayerCfg.WindowX1 = 239;
  pLayerCfg.WindowY0 = 0;
  pLayerCfg.WindowY1 = 319;
  pLayerCfg.PixelFormat = LTDC_PIXEL_FORMAT_RGB565;
  pLayerCfg.Alpha = 255;
  pLayerCfg.Alpha0 = 0;
  pLayerCfg.BlendingFactor1 = LTDC_BLENDING_FACTOR1_PAxCA;
  pLayerCfg.BlendingFactor2 = LTDC_BLENDING_FACTOR2_PAxCA;
  pLayerCfg.FBStartAdress = 0xD0000000;
  pLayerCfg.ImageWidth = 240;
  pLayerCfg.ImageHeight = 320;
  pLayerCfg.Backcolor.Blue = 0;
  pLayerCfg.Backcolor.Green = 0;
  pLayerCfg.Backcolor.Red = 0;
  if (HAL_LTDC_ConfigLayer(&hltdc, &pLayerCfg, 0) != HAL_OK)
  {
    Error_Handler();
  }

}

static void MX_SPI4_Init(void)
{

  /* SPI4 parameter configuration*/
  hspi4.Instance = SPI4;
  hspi4.Init.Mode = SPI_MODE_MASTER;
  hspi4.Init.Direction = SPI_DIRECTION_2LINES;
  hspi4.Init.DataSize = SPI_DATASIZE_8BIT;
  hspi4.Init.CLKPolarity = SPI_POLARITY_LOW;
  hspi4.Init.CLKPhase = SPI_PHASE_1EDGE;
  hspi4.Init.NSS = SPI_NSS_SOFT;
  hspi4.Init.BaudRatePrescaler = SPI_BAUDRATEPRESCALER_256;
  hspi4.Init.FirstBit = SPI_FIRSTBIT_MSB;
  hspi4.Init.TIMode = SPI_TIMODE_DISABLE;
  hspi4.Init.CRCCalculation = SPI_CRCCALCULATION_DISABLE;
  hspi4.Init.CRCPolynomial = 10;
  if (HAL_SPI_Init(&hspi4) != HAL_OK)
  {
    Error_Handler();
  }

}

static void MX_SPI5_Init(void)
{

  /* SPI5 parameter configuration*/
  hspi5.Instance = SPI5;
  hspi5.Init.Mode = SPI_MODE_MASTER;
  hspi5.Init.Direction = SPI_DIRECTION_2LINES;
  hspi5.Init.DataSize = SPI_DATASIZE_8BIT;
  hspi5.Init.CLKPolarity = SPI_POLARITY_LOW;
  hspi5.Init.CLKPhase = SPI_PHASE_1EDGE;
  hspi5.Init.NSS = SPI_NSS_SOFT;
  hspi5.Init.BaudRatePrescaler = SPI_BAUDRATEPRESCALER_16;
  hspi5.Init.FirstBit = SPI_FIRSTBIT_MSB;
  hspi5.Init.TIMode = SPI_TIMODE_DISABLE;
  hspi5.Init.CRCCalculation = SPI_CRCCALCULATION_DISABLE;
  hspi5.Init.CRCPolynomial = 10;
  if (HAL_SPI_Init(&hspi5) != HAL_OK)
  {
    Error_Handler();
  }

}

static void MX_TIM1_Init(void)
{

  TIM_ClockConfigTypeDef sClockSourceConfig = {0};
  TIM_MasterConfigTypeDef sMasterConfig = {0};

  htim1.Instance = TIM1;
  htim1.Init.Prescaler = 0;
  htim1.Init.CounterMode = TIM_COUNTERMODE_UP;
  htim1.Init.Period = 65535;
  htim1.Init.ClockDivision = TIM_CLOCKDIVISION_DIV1;
  htim1.Init.RepetitionCounter = 0;
  htim1.Init.AutoReloadPreload = TIM_AUTORELOAD_PRELOAD_DISABLE;
  if (HAL_TIM_Base_Init(&htim1) != HAL_OK)
  {
    Error_Handler();
  }
  sClockSourceConfig.ClockSource = TIM_CLOCKSOURCE_INTERNAL;
  if (HAL_TIM_ConfigClockSource(&htim1, &sClockSourceConfig) != HAL_OK)
  {
    Error_Handler();
  }
  sMasterConfig.MasterOutputTrigger = TIM_TRGO_RESET;
  sMasterConfig.MasterSlaveMode = TIM_MASTERSLAVEMODE_DISABLE;
  if (HAL_TIMEx_MasterConfigSynchronization(&htim1, &sMasterConfig) != HAL_OK)
  {
    Error_Handler();
  }

}

static void MX_TIM7_Init(void)
{

  TIM_MasterConfigTypeDef sMasterConfig = {0};

  htim7.Instance = TIM7;
  htim7.Init.Prescaler = 0;
  htim7.Init.CounterMode = TIM_COUNTERMODE_UP;
  htim7.Init.Period = 65535;
  htim7.Init.AutoReloadPreload = TIM_AUTORELOAD_PRELOAD_DISABLE;
  if (HAL_TIM_Base_Init(&htim7) != HAL_OK)
  {
    Error_Handler();
  }
  sMasterConfig.MasterOutputTrigger = TIM_TRGO_RESET;
  sMasterConfig.MasterSlaveMode = TIM_MASTERSLAVEMODE_DISABLE;
  if (HAL_TIMEx_MasterConfigSynchronization(&htim7, &sMasterConfig) != HAL_OK)
  {
    Error_Handler();
  }

}

static void MX_UART5_Init(void)
{

  huart5.Instance = UART5;
  huart5.Init.BaudRate = 115200;
  huart5.Init.WordLength = UART_WORDLENGTH_8B;
  huart5.Init.StopBits = UART_STOPBITS_1;
  huart5.Init.Parity = UART_PARITY_NONE;
  huart5.Init.Mode = UART_MODE_TX_RX;
  huart5.Init.HwFlowCtl = UART_HWCONTROL_NONE;
  huart5.Init.OverSampling = UART_OVERSAMPLING_16;
  if (HAL_UART_Init(&huart5) != HAL_OK)
  {
    Error_Handler();
  }

}

static void MX_USART1_UART_Init(void)
{

  huart1.Instance = USART1;
  huart1.Init.BaudRate = 115200;
  huart1.Init.WordLength = UART_WORDLENGTH_8B;
  huart1.Init.StopBits = UART_STOPBITS_1;
  huart1.Init.Parity = UART_PARITY_NONE;
  huart1.Init.Mode = UART_MODE_TX_RX;
  huart1.Init.HwFlowCtl = UART_HWCONTROL_NONE;
  huart1.Init.OverSampling = UART_OVERSAMPLING_16;
  if (HAL_UART_Init(&huart1) != HAL_OK)
  {
    Error_Handler();
  }

}

/* FMC initialization function */
static void MX_FMC_Init(void)
{

  FMC_SDRAM_TimingTypeDef SdramTiming = {0};

  /** Perform the SDRAM1 memory initialization sequence
  */
  hsdram1.Instance = FMC_SDRAM_DEVICE;
  /* hsdram1.Init */
  hsdram1.Init.SDBank = FMC_SDRAM_BANK2;
  hsdram1.Init.ColumnBitsNumber = FMC_SDRAM_COLUMN_BITS_NUM_8;
  hsdram1.Init.RowBitsNumber = FMC_SDRAM_ROW_BITS_NUM_12;
  hsdram1.Init.MemoryDataWidth = FMC_SDRAM_MEM_BUS_WIDTH_16;
  hsdram1.Init.InternalBankNumber = FMC_SDRAM_INTERN_BANKS_NUM_4;
  hsdram1.Init.CASLatency = FMC_SDRAM_CAS_LATENCY_3;
  hsdram1.Init.WriteProtection = FMC_SDRAM_WRITE_PROTECTION_DISABLE;
  hsdram1.Init.SDClockPeriod = FMC_SDRAM_CLOCK_PERIOD_2;
  hsdram1.Init.ReadBurst = FMC_SDRAM_RBURST_DISABLE;
  hsdram1.Init.ReadPipeDelay = FMC_SDRAM_RPIPE_DELAY_1;
  /* SdramTiming */
  SdramTiming.LoadToActiveDelay = 2;
  SdramTiming.ExitSelfRefreshDelay = 7;
  SdramTiming.SelfRefreshTime = 4;
  SdramTiming.RowCycleDelay = 7;
  SdramTiming.WriteRecoveryTime = 3;
  SdramTiming.RPDelay = 2;
  SdramTiming.RCDDelay = 2;

  if (HAL_SDRAM_Init(&hsdram1, &SdramTiming) != HAL_OK)
  {
    Error_Handler( );
  }

}

static void MX_GPIO_Init(void)
{
  GPIO_InitTypeDef GPIO_InitStruct = {0};

  /* GPIO Ports Clock Enable */
  __HAL_RCC_GPIOE_CLK_ENABLE();
  __HAL_RCC_GPIOC_CLK_ENABLE();
  __HAL_RCC_GPIOF_CLK_ENABLE();
  __HAL_RCC_GPIOH_CLK_ENABLE();
  __HAL_RCC_GPIOA_CLK_ENABLE();
  __HAL_RCC_GPIOB_CLK_ENABLE();
  __HAL_RCC_GPIOG_CLK_ENABLE();
  __HAL_RCC_GPIOD_CLK_ENABLE();

  /*Configure GPIO pin Output Level */
  HAL_GPIO_WritePin(GPIOC, NCS_MEMS_SPI_Pin|CSX_Pin|OTG_FS_PSO_Pin, GPIO_PIN_RESET);

  /*Configure GPIO pin Output Level */
  HAL_GPIO_WritePin(ACP_RST_GPIO_Port, ACP_RST_Pin, GPIO_PIN_RESET);

  /*Configure GPIO pin Output Level */
  HAL_GPIO_WritePin(GPIOD, RDX_Pin|WRX_DCX_Pin, GPIO_PIN_RESET);

  /*Configure GPIO pin Output Level */
  HAL_GPIO_WritePin(GPIOG, LD3_Pin|LD4_Pin, GPIO_PIN_RESET);

  /*Configure GPIO pins : NCS_MEMS_SPI_Pin CSX_Pin OTG_FS_PSO_Pin */
  GPIO_InitStruct.Pin = NCS_MEMS_SPI_Pin|CSX_Pin|OTG_FS_PSO_Pin;
  GPIO_InitStruct.Mode = GPIO_MODE_OUTPUT_PP;
  GPIO_InitStruct.Pull = GPIO_NOPULL;
  GPIO_InitStruct.Speed = GPIO_SPEED_FREQ_LOW;
  HAL_GPIO_Init(GPIOC, &GPIO_InitStruct);

  /*Configure GPIO pin : PA0 */
  GPIO_InitStruct.Pin = GPIO_PIN_0;
  GPIO_InitStruct.Mode = GPIO_MODE_IT_RISING;
  GPIO_InitStruct.Pull = GPIO_NOPULL;
  HAL_GPIO_Init(GPIOA, &GPIO_InitStruct);

  /*Configure GPIO pin : MEMS_INT1_Pin */
  GPIO_InitStruct.Pin = MEMS_INT1_Pin;
  GPIO_InitStruct.Mode = GPIO_MODE_IT_FALLING;
  GPIO_InitStruct.Pull = GPIO_PULLUP;
  HAL_GPIO_Init(MEMS_INT1_GPIO_Port, &GPIO_InitStruct);

  /*Configure GPIO pins : MEMS_INT2_Pin TP_INT1_Pin */
  GPIO_InitStruct.Pin = MEMS_INT2_Pin|TP_INT1_Pin;
  GPIO_InitStruct.Mode = GPIO_MODE_EVT_RISING;
  GPIO_InitStruct.Pull = GPIO_NOPULL;
  HAL_GPIO_Init(GPIOA, &GPIO_InitStruct);

  /*Configure GPIO pin : ACP_RST_Pin */
  GPIO_InitStruct.Pin = ACP_RST_Pin;
  GPIO_InitStruct.Mode = GPIO_MODE_OUTPUT_PP;
  GPIO_InitStruct.Pull = GPIO_NOPULL;
  GPIO_InitStruct.Speed = GPIO_SPEED_FREQ_LOW;
  HAL_GPIO_Init(ACP_RST_GPIO_Port, &GPIO_InitStruct);

  /*Configure GPIO pin : OTG_FS_OC_Pin */
  GPIO_InitStruct.Pin = OTG_FS_OC_Pin;
  GPIO_InitStruct.Mode = GPIO_MODE_EVT_RISING;
  GPIO_InitStruct.Pull = GPIO_NOPULL;
  HAL_GPIO_Init(OTG_FS_OC_GPIO_Port, &GPIO_InitStruct);

  /*Configure GPIO pin : BOOT1_Pin */
  GPIO_InitStruct.Pin = BOOT1_Pin;
  GPIO_InitStruct.Mode = GPIO_MODE_INPUT;
  GPIO_InitStruct.Pull = GPIO_NOPULL;
  HAL_GPIO_Init(BOOT1_GPIO_Port, &GPIO_InitStruct);

  /*Configure GPIO pin : TE_Pin */
  GPIO_InitStruct.Pin = TE_Pin;
  GPIO_InitStruct.Mode = GPIO_MODE_INPUT;
  GPIO_InitStruct.Pull = GPIO_NOPULL;
  HAL_GPIO_Init(TE_GPIO_Port, &GPIO_InitStruct);

  /*Configure GPIO pins : RDX_Pin WRX_DCX_Pin */
  GPIO_InitStruct.Pin = RDX_Pin|WRX_DCX_Pin;
  GPIO_InitStruct.Mode = GPIO_MODE_OUTPUT_PP;
  GPIO_InitStruct.Pull = GPIO_NOPULL;
  GPIO_InitStruct.Speed = GPIO_SPEED_FREQ_LOW;
  HAL_GPIO_Init(GPIOD, &GPIO_InitStruct);

  /*Configure GPIO pins : LD3_Pin LD4_Pin */
  GPIO_InitStruct.Pin = LD3_Pin|LD4_Pin;
  GPIO_InitStruct.Mode = GPIO_MODE_OUTPUT_PP;
  GPIO_InitStruct.Pull = GPIO_NOPULL;
  GPIO_InitStruct.Speed = GPIO_SPEED_FREQ_LOW;
  HAL_GPIO_Init(GPIOG, &GPIO_InitStruct);

  /* EXTI interrupt init*/
  HAL_NVIC_SetPriority(EXTI0_IRQn, 5, 0);
  HAL_NVIC_EnableIRQ(EXTI0_IRQn);

  /* USER CODE BEGIN MX_GPIO_Init_2 */
  GPIO_InitStruct.Pin = GPIO_PIN_1; // Używamy PC1
	GPIO_InitStruct.Mode = GPIO_MODE_IT_RISING_FALLING; // Reaguj na zmianę 0->1 i 1->0
	GPIO_InitStruct.Pull = GPIO_PULLDOWN; // Domyślnie w dół (jeśli kabel się urwie to brak wifi)
	HAL_GPIO_Init(GPIOC, &GPIO_InitStruct);

	// 3. Włącz przerwanie w NVIC (kontroler przerwań)
	// PC1 korzysta z linii EXTI1
	HAL_NVIC_SetPriority(EXTI1_IRQn, 0, 0); // Najwyższy priorytet!
	HAL_NVIC_EnableIRQ(EXTI1_IRQn);
  /* USER CODE END MX_GPIO_Init_2 */
}

/* USER CODE BEGIN 4 */

void DrawHeader(void)
{
    BSP_LCD_SetTextColor(LCD_COLOR_BLACK);
    BSP_LCD_FillRect(0, 0, 240, 32);

    BSP_LCD_SetBackColor(LCD_COLOR_BLACK);
    BSP_LCD_SetTextColor(LCD_COLOR_WHITE);
    BSP_LCD_SetFont(&Font16);

    switch (currentSensor)
    {
        case 0:
            BSP_LCD_DisplayStringAt(0, 10, (uint8_t *)"Thermometer", CENTER_MODE);
            break;
        case 1:
            BSP_LCD_DisplayStringAt(0, 10, (uint8_t *)"SpO2 & HR", CENTER_MODE);
            break;
        case 2:
            BSP_LCD_DisplayStringAt(0, 10, (uint8_t *)"Stress Level", CENTER_MODE);
            break;
        case 3:
            BSP_LCD_DisplayStringAt(0, 10, (uint8_t *)"Live ECG", CENTER_MODE);
            break;
    }

    BSP_LCD_SetTextColor(LCD_COLOR_WHITE);
    BSP_LCD_DrawHLine(0, 32, 240);

    BSP_LCD_SetTextColor(LCD_COLOR_WHITE);
}

void DrawBottomButtons(void)
{
    BSP_LCD_SetTextColor(LCD_COLOR_BLACK);
    BSP_LCD_FillRect(0, BUTTON_AREA_Y_START, 240, BUTTON_HEIGHT);

    BSP_LCD_SetTextColor(LCD_COLOR_WHITE);
    BSP_LCD_DrawVLine(80, BUTTON_AREA_Y_START, BUTTON_HEIGHT);
    BSP_LCD_DrawVLine(160, BUTTON_AREA_Y_START, BUTTON_HEIGHT);

    BSP_LCD_DrawHLine(0, BUTTON_AREA_Y_START, 240);

    BSP_LCD_SetBackColor(LCD_COLOR_BLACK);
    BSP_LCD_SetTextColor(LCD_COLOR_WHITE);
    BSP_LCD_SetFont(&Font16);

    BSP_LCD_DisplayStringAt(11, BUTTON_AREA_Y_START + 15, (uint8_t *)"< PREV", LEFT_MODE);

    if (measurementActive) {
        BSP_LCD_SetTextColor(LCD_COLOR_RED);
        BSP_LCD_DisplayStringAt(4, BUTTON_AREA_Y_START + 15, (uint8_t *)"STOP", CENTER_MODE);
    } else {
        BSP_LCD_SetTextColor(LCD_COLOR_GREEN);
        BSP_LCD_DisplayStringAt(4, BUTTON_AREA_Y_START + 15, (uint8_t *)"START", CENTER_MODE);
    }

    BSP_LCD_SetTextColor(LCD_COLOR_WHITE);

    BSP_LCD_DisplayStringAt(0, BUTTON_AREA_Y_START + 15, (uint8_t *)"NEXT >", RIGHT_MODE);
}

void StartTouchTask(const void *argument)
{
    TS_StateTypeDef ts;
    uint8_t wasTouched = 0;

    printf("Touch task started\r\n");
    osDelay(500);

    for (;;)
    {

        BSP_TS_GetState(&ts);

        if (ts.TouchDetected)
        {
            if (!wasTouched)
            {
                uint16_t y = 320 - ts.Y;
                uint16_t x = 240 - ts.X;

                if (y >= BUTTON_AREA_Y_START)
                {
                    if (x < 80)
                    {
                        currentSensor = (currentSensor + 1) % 4;
                        printf("BTN: PREV -> Sensor %d\r\n", currentSensor);

                        memset(&bloodOxyBuffer, 0, sizeof(BloodOxyBuffer));
                    }
                    else if (x < 160)
                    {
                        measurementActive = !measurementActive;
                        printf("BTN: %s\r\n", measurementActive ? "START" : "STOP");

                        if (measurementActive == 0) {
                            memset(&bloodOxyBuffer, 0, sizeof(BloodOxyBuffer));
                        }
                    }
                    else
                    {
                        currentSensor = (currentSensor + 3) % 4;
                        printf("BTN: NEXT -> Sensor %d\r\n", currentSensor);

                        memset(&bloodOxyBuffer, 0, sizeof(BloodOxyBuffer));
                    }

                    updateScreenFlag = 1;
                }
            }
            wasTouched = 1;
        }
        else
        {
            wasTouched = 0;
        }

        osDelay(50);
    }
}
void GetTimeFromESP(void)
{
    const char* cmd = "GET_TIME\n";
    static uint8_t rxBuf[128]; // Mały bufor wystarczy na czas
    rtc_base_time = 0;

    printf("--- SYNC: TIME ---\r\n");

    while (rtc_base_time == 0)
    {
        // 1. Flush
        if(__HAL_UART_GET_FLAG(&huart5, UART_FLAG_RXNE)) {
             volatile uint8_t d = (uint8_t)(huart5.Instance->DR & 0xFF); (void)d;
        }
        __HAL_UART_CLEAR_OREFLAG(&huart5);
        memset(rxBuf, 0, sizeof(rxBuf));

        // 2. Wyślij
        HAL_UART_Transmit(&huart5, (uint8_t*)cmd, strlen(cmd), HAL_MAX_DELAY);

        // 3. Odbierz (Czekaj na '{')
        uint8_t ch = 0;
        if (HAL_UART_Receive(&huart5, &ch, 1, 2000) == HAL_OK)
        {
            if (ch == '{') {
                int idx = 0;
                rxBuf[idx++] = ch;

                // Szybka pętla odbioru
                uint32_t to = 1000000;
                while (to-- > 0) {
                    if (huart5.Instance->SR & UART_FLAG_RXNE) {
                        uint8_t d = (uint8_t)(huart5.Instance->DR & 0xFF);
                        if (d == '\r') continue;
                        rxBuf[idx++] = d;
                        if (d == '\n') break;
                        if (idx >= 127) break;
                        to = 1000000; // Reset timeoutu po znaku
                    }
                }
                rxBuf[idx] = '\0';

                // Parsowanie
                char *ptr = strstr((char*)rxBuf, "\"rtc\":");
                if (ptr) {
                    rtc_base_time = atoi(ptr + 6);
                    if (rtc_base_time > 1600000000) {
                        printf(">> TIME OK: %lu\r\n", rtc_base_time);
                        return; // SUKCES
                    }
                }
            }
        }
        printf("Retry Time...\r\n");
        osDelay(500);
    }
}

void GetConfigFromESP(void)
{
    const char* cmd = "GET_CONFIG\n";
    static uint8_t rxBuf[512]; // Większy bufor na config
    uint8_t success = 0;

    printf("--- SYNC: CONFIG ---\r\n");

    while (!success)
    {
        // 1. Flush
        if(__HAL_UART_GET_FLAG(&huart5, UART_FLAG_RXNE)) {
             volatile uint8_t d = (uint8_t)(huart5.Instance->DR & 0xFF); (void)d;
        }
        __HAL_UART_CLEAR_OREFLAG(&huart5);
        memset(rxBuf, 0, sizeof(rxBuf));

        // 2. Wyślij
        HAL_UART_Transmit(&huart5, (uint8_t*)cmd, strlen(cmd), HAL_MAX_DELAY);

        // 3. Odbierz
        uint8_t ch = 0;
        if (HAL_UART_Receive(&huart5, &ch, 1, 2000) == HAL_OK)
        {
            if (ch == '{') {
                int idx = 0;
                rxBuf[idx++] = ch;

                uint32_t to = 2000000;
                while (to-- > 0) {
                    if (huart5.Instance->SR & UART_FLAG_RXNE) {
                        uint8_t d = (uint8_t)(huart5.Instance->DR & 0xFF);
                        if (d == '\r') continue;
                        rxBuf[idx++] = d;
                        if (d == '\n') break;
                        if (idx >= 511) break;
                        to = 2000000;
                    }
                }
                rxBuf[idx] = '\0';

                printf("RX CFG: %s", rxBuf);

                // Parsowanie Configu
                char *ptr;
                ptr = strstr((char*)rxBuf, "\"t_min\":"); if (ptr) { CFG_TEMP_LOW = strtof(ptr + 8, NULL); success=1; }
                ptr = strstr((char*)rxBuf, "\"t_max\":"); if (ptr) { CFG_TEMP_HIGH = strtof(ptr + 8, NULL); success=1; }
                ptr = strstr((char*)rxBuf, "\"sp_min\":"); if (ptr) { CFG_SPO2_LOW = atoi(ptr + 9); success=1; }
                ptr = strstr((char*)rxBuf, "\"hr_min\":"); if (ptr) CFG_HR_LOW = atoi(ptr + 9);
                ptr = strstr((char*)rxBuf, "\"hr_max\":"); if (ptr) CFG_HR_HIGH = atoi(ptr + 9);
                ptr = strstr((char*)rxBuf, "\"gsr1\":"); if (ptr) CFG_GSR_STRESS = atoi(ptr + 7);
                ptr = strstr((char*)rxBuf, "\"gsr2\":"); if (ptr) CFG_GSR_NEUTRAL = atoi(ptr + 7);

                if (success) {
                    printf(">> CONFIG OK!\r\n");
                    return;
                }
            }
        }
        printf("Retry Config...\r\n");
        osDelay(500);
    }
}

#define ECG_BATCH_SIZE 50 // Wysyłamy co 50 próbek
static int32_t ecgBatchBuffer[ECG_BATCH_SIZE];
static uint16_t ecgBatchIndex = 0;

// Bufor na JSON (50 liczb * ~5 cyfr + nagłówek)
char ecgTxBuffer[512];

void myStartDefaultTask(const void *argument)
{
	osDelay(2000);
    const char* hello = "HELLO STM32 UART5\r\n";
    HAL_UART_Transmit(&huart5, (uint8_t*)hello, strlen(hello), HAL_MAX_DELAY);
    osDelay(200);

        // 1. Pobierz czas
	GetTimeFromESP();

	osDelay(200); // Mała przerwa między transakcjami

	// 2. Pobierz konfigurację
	GetConfigFromESP();

    if (HAL_GPIO_ReadPin(GPIOC, GPIO_PIN_1) == GPIO_PIN_RESET)
        {
            printf("STARTUP CHECK: NO WIFI SIGNAL DETECTED!\r\n");

            // Rysuj Czerwony Ekran
            BSP_LCD_Clear(LCD_COLOR_BLACK);
            BSP_LCD_SetBackColor(LCD_COLOR_RED);
            BSP_LCD_SetTextColor(LCD_COLOR_WHITE);
            BSP_LCD_SetFont(&Font24);
            BSP_LCD_DisplayStringAt(0, 120, (uint8_t*)"NO WIFI", CENTER_MODE);
            BSP_LCD_SetFont(&Font16);
            BSP_LCD_DisplayStringAt(0, 160, (uint8_t*)"Check Connection...", CENTER_MODE);

            // Zablokuj system dopóki nie pojawi się stan WYSOKI (WiFi wróci)
            while (HAL_GPIO_ReadPin(GPIOC, GPIO_PIN_1) == GPIO_PIN_RESET)
            {
                HAL_GPIO_TogglePin(GPIOG, LD3_Pin); // Miganie diodą
                osDelay(200); // Tutaj możemy użyć osDelay bo nie jesteśmy w przerwaniu
            }

            // WiFi wróciło - czyścimy ekran i idziemy dalej
            printf("STARTUP CHECK: WIFI DETECTED!\r\n");
            BSP_LCD_Clear(LCD_COLOR_BLACK);
            DrawHeader();
            DrawBottomButtons();
        }

    printf("Board powering on and starting tasks\r\n");

    if (MLX90614_Init_I2C(&hi2c3, 0x5A)) {
        printf("MLX90614 sensor ready\r\n");
    } else {
        printf("MLX90614 sensor not found\r\n");
    }

    if (BoodOxy_Init_I2C(&hi2c3, 0x57)) {
        printf("BloodOxy sensor ready\r\n");
        BoodOxy_SensorStartCollect();
    } else {
        printf("BloodOxy sensor not found\r\n");
    }
    MAX30003_Init(&max30003, &hspi4, MAX30003_CS_GPIO_Port, MAX30003_CS_Pin);

    HAL_Delay(100);

	if (!MAX30003_ReadDeviceID(&max30003)) {
		printf("MAX30003 ID error (Check Wiring!)\r\n");
	} else {
		printf("MAX30003 ready\r\n");
	}

	systemStartupComplete = 1;
	measurementActive = 0;
	DrawBottomButtons();

	char uart5Msg[256];

        for (;;) {

        	if (measurementActive == 0) {
    			osDelay(100);
    			continue;
    		}

            switch (currentSensor) {

            // ====================================================================
            // CASE 0: TEMPERATURA
            // ====================================================================
            case 0:
                if (MLX90614_ReadAmbientTemp(&mlxData.ambient) == HAL_OK) {
                    if (MLX90614_ReadObjectTemp(&mlxData.object) != HAL_OK) {
                        mlxData.object = 0.0f;
                    }
                    osMessagePut(tempQueueHandle, (uint32_t)&mlxData, 0);

                    uint8_t isAlarm = 0;
                    if (mlxData.object >= CFG_TEMP_HIGH || mlxData.object <= CFG_TEMP_LOW) {
                        isAlarm = 1;
                    }

                    uint32_t timestamp = rtc_base_time + HAL_GetTick() / 1000;
                    char payload[96];
                    snprintf(payload, sizeof(payload),
                             "{\"timestamp\":%lu,\"ambient\":%.2f,\"object\":%.2f,\"alarm\":%d}",
                             timestamp, mlxData.ambient, mlxData.object, isAlarm);

                    uint8_t crc = calcChecksum(payload, strlen(payload));
                    snprintf(uart5Msg, sizeof(uart5Msg), "%s,\"crc\":%d}\r\n", payload, crc);

                    printf("Timestamp: %lu, Ambient: %.2f C, Object: %.2f C, CRC: %d\r\n",
                           timestamp, mlxData.ambient, mlxData.object, crc);

                    // --- POPRAWIONA PĘTLA RETRY ---
                    for (int attempt = 0; attempt < MAX_RETRIES; attempt++) {
                        printf("Sent (try %d): %s", attempt + 1, uart5Msg);

                        // 1. Wysyłamy
                        HAL_UART_Transmit(&huart5, (uint8_t*)uart5Msg, strlen(uart5Msg), HAL_MAX_DELAY);

                        // 2. Czekamy na ACK (500ms timeout)
                        if (waitForAck(&huart5, 500)) {
                            printf("ACK received\r\n\n");
                            break; // Sukces, wychodzimy z pętli
                        } else {
                            printf("NACK or Timeout. Retrying...\r\n");
                            osDelay(100); // Krótka przerwa przed ponowieniem
                        }
                    }
                    // ------------------------------

                } else {
                    printf("Temperature read error\r\n");
                }
                osDelay(2000);
                break;

            // ====================================================================
            // CASE 1: SPO2 i PULS
            // ====================================================================
            case 1:
            {
                BoodOxyData tempData;
                if (BoodOxy_GetHeartbeatSPO2(&tempData) == HAL_OK) {
                    oxyData = tempData;

                    if (tempData.spo2 > 0 && tempData.spo2 <= 100 &&
                        tempData.heartbeat > 0 && tempData.heartbeat <= 250) {

                        for (int i = BLOOD_OXY_BUFFER_SIZE - 1; i > 0; i--) {
                            bloodOxyBuffer.spo2_values[i] = bloodOxyBuffer.spo2_values[i-1];
                            bloodOxyBuffer.hr_values[i] = bloodOxyBuffer.hr_values[i-1];
                        }
                        bloodOxyBuffer.spo2_values[0] = tempData.spo2;
                        bloodOxyBuffer.hr_values[0] = tempData.heartbeat;

                        if (bloodOxyBuffer.valid_count < BLOOD_OXY_BUFFER_SIZE) {
                            bloodOxyBuffer.valid_count++;
                        }
                    }

                    if (bloodOxyBuffer.valid_count >= 3) {
                        int32_t avg_spo2 = 0;
                        int32_t avg_hr = 0;
                        for (int i = 0; i < 3; i++) {
                            avg_spo2 += bloodOxyBuffer.spo2_values[i];
                            avg_hr += bloodOxyBuffer.hr_values[i];
                        }
                        avg_spo2 /= 3;
                        avg_hr /= 3;
                        oxyData.spo2 = avg_spo2;
    					oxyData.heartbeat = avg_hr;

    					osMessagePut(oxyQueueHandle, (uint32_t)&oxyData, 0);
    					uint8_t isAlarm = 0;
    					if (avg_spo2 < CFG_SPO2_LOW || avg_hr > CFG_HR_HIGH || avg_hr < CFG_HR_LOW) {
    					    isAlarm = 1;
    					}

                        uint32_t timestamp = rtc_base_time + HAL_GetTick() / 1000;
                        char payload[96];
                        snprintf(payload, sizeof(payload),
                                 "{\"timestamp\":%lu,\"spo2\":%ld,\"hr\":%ld,\"alarm\":%d}",
                                 timestamp, avg_spo2, avg_hr, isAlarm);

                        uint8_t crc = calcChecksum(payload, strlen(payload));
                        snprintf(uart5Msg, sizeof(uart5Msg), "%s,\"crc\":%d}\r\n", payload, crc);

                        printf("Timestamp: %lu, SpO2: %ld%%, HR: %ld bpm, CRC: %d\r\n",
                               timestamp, avg_spo2, avg_hr, crc);

                        // --- POPRAWIONA PĘTLA RETRY ---
                        for (int attempt = 0; attempt < MAX_RETRIES; attempt++) {
                            printf("Sent (try %d): %s", attempt + 1, uart5Msg);

                            HAL_UART_Transmit(&huart5, (uint8_t*)uart5Msg, strlen(uart5Msg), HAL_MAX_DELAY);

                            if (waitForAck(&huart5, 500)) {
                                printf("ACK received\r\n\n");
                                break;
                            } else {
                                printf("NACK or Timeout. Retrying...\r\n");
                                osDelay(100);
                            }
                        }
                        // ------------------------------
                        osDelay(5000); // Dłuższa przerwa po udanym pomiarze
                    } else {
                        printf("Waiting for more valid samples (%d/3)...\r\n", bloodOxyBuffer.valid_count);
                        osDelay(1000);
                    }
                } else {
                    printf("BloodOxy read error\r\n");
                    osDelay(1000);
                }
                osDelay(2000);
                break;
            }

            // ====================================================================
            // CASE 2: GSR (STRES)
            // ====================================================================
            case 2:
            {
                ADC_ChannelConfTypeDef sConfig = {0};
                sConfig.Channel = ADC_CHANNEL_13;
                sConfig.Rank = 1;
                sConfig.SamplingTime = ADC_SAMPLETIME_15CYCLES;

                if (HAL_ADC_ConfigChannel(&hadc1, &sConfig) != HAL_OK) { Error_Handler(); }

                uint32_t gsrSum = 0;
                for (int i = 0; i < 10; i++) {
                    HAL_ADC_Start(&hadc1);
                    if (HAL_ADC_PollForConversion(&hadc1, HAL_MAX_DELAY) == HAL_OK) {
                        gsrSum += HAL_ADC_GetValue(&hadc1);
                    }
                }
                uint32_t gsrAvg = gsrSum / 10;

                const char* mood = "Unknown";
                if (gsrAvg < CFG_GSR_STRESS) mood = "Stressed";
                else if (gsrAvg >= CFG_GSR_STRESS && gsrAvg <= CFG_GSR_NEUTRAL) mood = "Neutral";
                else mood = "Relaxed";

                uint8_t isAlarm = 0;
                // Jeśli GSR wskazuje na wysoki stres ("Stressed"), traktujemy to jako alarm
                if (strcmp(mood, "Stressed") == 0) {
                    isAlarm = 1;
                }

                strncpy((char*)gsrData.mood, mood, 16);
                gsrData.value = gsrAvg;
                osMessagePut(gsrQueueHandle, (uint32_t)&gsrData, 0);

                uint32_t timestamp = rtc_base_time + HAL_GetTick() / 1000;
                char payload[128];
                snprintf(payload, sizeof(payload),
                         "{\"timestamp\":%lu,\"gsr\":%lu,\"mood\":\"%s\",\"alarm\":%d}",
                         timestamp, gsrAvg, mood, isAlarm);

                uint8_t crc = calcChecksum(payload, strlen(payload));
                snprintf(uart5Msg, sizeof(uart5Msg), "%s,\"crc\":%d}\r\n", payload, crc);

                printf("Timestamp: %lu, GSR: %lu, Mood: %s, CRC: %d\r\n", timestamp, gsrAvg, mood, crc);

                // --- POPRAWIONA PĘTLA RETRY ---
                for (int attempt = 0; attempt < MAX_RETRIES; attempt++) {
                    printf("Sent (try %d): %s", attempt + 1, uart5Msg);

                    HAL_UART_Transmit(&huart5, (uint8_t*)uart5Msg, strlen(uart5Msg), HAL_MAX_DELAY);

                    if (waitForAck(&huart5, 500)) {
                        printf("ACK received\r\n\n");
                        break;
                    } else {
                        printf("NACK or Timeout. Retrying...\r\n");
                        osDelay(100);
                    }
                }
                // ------------------------------
            }
            osDelay(1000);
            break;

            // ====================================================================
            // CASE 3: EKG (STREAMING)
            // ====================================================================
            case 3:
            {
                uint32_t status = MAX30003_ReadReg(&max30003, 0x01);

                if (status & 0x800000) { // Dane dostępne
                    int32_t ecg_val;
                    while(MAX30003_GetECG_Sample(&max30003, &ecg_val)) {

                        osMessagePut(ecgQueueHandle, ecg_val, 0); // Wykres

                        if (ecgBatchIndex < ECG_BATCH_SIZE) {
                            ecgBatchBuffer[ecgBatchIndex++] = ecg_val;
                        }

                        // WYSYŁKA PACZKI
                        if (ecgBatchIndex >= ECG_BATCH_SIZE) {
                            uint32_t timestamp = rtc_base_time + HAL_GetTick() / 1000;

                            // Budowanie JSON
                            int len = snprintf(ecgTxBuffer, sizeof(ecgTxBuffer), "{\"timestamp\":%lu,\"ecg\":[", timestamp);
                            for (int i = 0; i < ECG_BATCH_SIZE; i++) {
                                if (len >= sizeof(ecgTxBuffer) - 20) break;
                                len += snprintf(ecgTxBuffer + len, sizeof(ecgTxBuffer) - len, "%ld%s", ecgBatchBuffer[i], (i < ECG_BATCH_SIZE - 1) ? "," : "");
                            }
                            len += snprintf(ecgTxBuffer + len, sizeof(ecgTxBuffer) - len, "]}");

                            uint8_t crc = calcChecksum(ecgTxBuffer, len);
                            snprintf(ecgTxBuffer + len, sizeof(ecgTxBuffer) - len, ",\"crc\":%d}\r\n", crc);

                            // --- WYSYŁKA EKG Z RETRY ---
                            // Dla EKG retry jest ryzykowne (może zatkać bufor), ale spróbujmy raz lub dwa
                            for (int attempt = 0; attempt < 2; attempt++) {
                                HAL_UART_Transmit(&huart5, (uint8_t*)ecgTxBuffer, strlen(ecgTxBuffer), HAL_MAX_DELAY);

                                // Krótszy timeout dla EKG, bo to strumień
                                if (waitForAck(&huart5, 200)) {
                                    break;
                                }
                                // Jeśli NACK, próbujemy jeszcze raz (pętla)
                            }
                            // ---------------------------

                            ecgBatchIndex = 0; // Reset bufora
                        }
                    }
                }

                // Obsługa błędu FIFO
                if (status & 0x400000) {
                    MAX30003_WriteReg(&max30003, 0x00, 0x000000);
                    MAX30003_WriteReg(&max30003, 0x09, 0x000000);
                    ecgBatchIndex = 0;
                }
                osDelay(2);
                break;
            }

    		} // End Switch
    	} // End For
}

uint8_t calcChecksum(const char* str, size_t len) {
    uint8_t sum = 0;
    for (size_t i = 0; i < len; i++) {
        sum += (uint8_t)str[i];
    }
    return sum;
}

bool waitForAck(UART_HandleTypeDef* uart, uint32_t timeout_ms) {
    // !!! WAŻNE: USUWAMY CZYSZCZENIE BUFORA !!!
    // ESP32 jest teraz tak szybkie, że ACK już tu prawdopodobnie czeka w buforze sprzętowym STM32.
    // Jeśli zrobimy flush/read dummy, to skasujemy właściwy ACK.

    uint8_t ch;
    char ackBuf[32] = {0}; // Zwiększyłem bufor
    int idx = 0;
    uint32_t start = HAL_GetTick();

    while ((HAL_GetTick() - start) < timeout_ms) {
        // Krótki timeout na znak, żeby nie blokować pętli, ale pętla główna trwa timeout_ms
        if (HAL_UART_Receive(uart, &ch, 1, 5) == HAL_OK) {

            // Ignorujemy znak powrotu karetki '\r'
            if (ch == '\r') continue;

            // Jeśli koniec linii '\n' -> kończymy odbieranie
            if (ch == '\n') {
                break;
            }

            // Zbieramy znaki (zabezpieczenie przed przepełnieniem)
            if (idx < sizeof(ackBuf) - 1) {
                ackBuf[idx++] = ch;
            }
        }
    }

    ackBuf[idx] = '\0'; // Zamykamy string

    // Opcjonalnie: Debugowanie, odkomentuj jeśli nadal nie działa
    // if (idx > 0) printf("[DEBUG ACK] Recv: '%s'\r\n", ackBuf);

    // Sprawdzamy czy odebrano ACK
    // Używamy strstr zamiast strcmp, na wypadek gdyby na początku były jakieś śmieci (np. 0x00)
    if (strstr(ackBuf, "ACK") != NULL) return true;

    // Obsługa NACK
    if (strstr(ackBuf, "NACK") != NULL) return false;

    return false;
}

/* To wklej do pliku stm32f4xx_it.c na samym dole */

/* USER CODE END 4 */

void StartDefaultTask(const void *argument)
{
  /* init code for USB_HOST */
  MX_USB_HOST_Init();
  for(;;)
  {
    osDelay(1);
  }
}

void HAL_TIM_PeriodElapsedCallback(TIM_HandleTypeDef *htim)
{
  if (htim->Instance == TIM6)
  {
    HAL_IncTick();
  }
}

void Error_Handler(void)
{
  __disable_irq();
  while (1)
  {
  }
}
